VERSION ""

NS_ :

BS_:

BU_: EBCM EON CAM RADAR PCM EPS VSA SCM BDY XXX EPB EO E

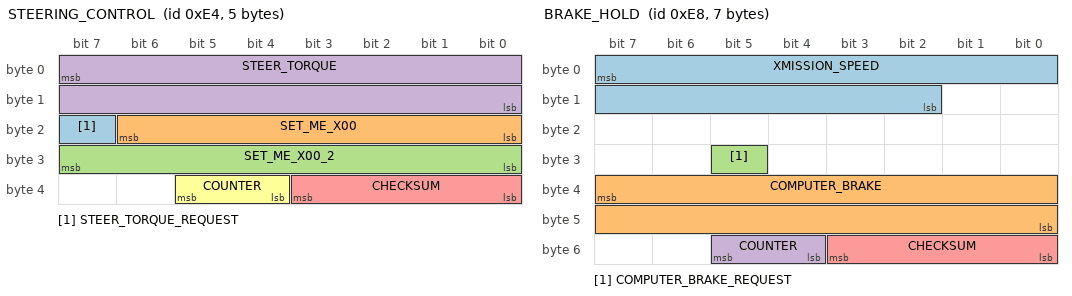
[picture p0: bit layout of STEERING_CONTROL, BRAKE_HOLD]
BO_ 228 STEERING_CONTROL: 5 EON
 SG_ STEER_TORQUE_REQUEST : 23|1@0+ (1,0) [0|1] "" EPS
 SG_ SET_ME_X00 : 22|7@0+ (1,0) [0|127] "" EPS
 SG_ SET_ME_X00_2 : 31|8@0+ (1,0) [0|0] "" EPS
 SG_ STEER_TORQUE : 7|16@0- (1,0) [-4096|4096] "" EPS
 SG_ CHECKSUM : 35|4@0+ (1,0) [0|15] "" EPS
 SG_ COUNTER : 37|2@0+ (1,0) [0|3] "" EPS

BO_ 232 BRAKE_HOLD: 7 XXX
 SG_ XMISSION_SPEED : 7|14@0- (1,0) [1|0] "" XXX
 SG_ COMPUTER_BRAKE : 39|16@0+ (1,0) [0|0] "" XXX
 SG_ COMPUTER_BRAKE_REQUEST : 29|1@0+ (1,0) [0|0] "" XXX
 SG_ COUNTER : 53|2@0+ (1,0) [0|3] "" XXX
 SG_ CHECKSUM : 51|4@0+ (1,0) [0|15] "" XXX

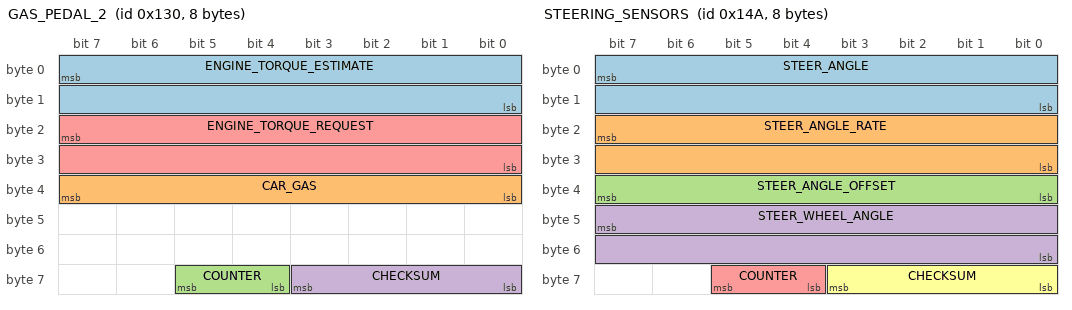
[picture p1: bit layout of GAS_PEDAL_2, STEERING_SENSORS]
BO_ 304 GAS_PEDAL_2: 8 PCM
 SG_ ENGINE_TORQUE_ESTIMATE : 7|16@0- (1,0) [-1000|1000] "Nm" EON
 SG_ CAR_GAS : 39|8@0+ (1,0) [0|255] "" EON
 SG_ COUNTER : 61|2@0+ (1,0) [0|3] "" EON
 SG_ CHECKSUM : 59|4@0+ (1,0) [0|15] "" EON
 SG_ ENGINE_TORQUE_REQUEST : 23|16@0- (0.01,0) [-1000|1000] "Nm" EON

BO_ 330 STEERING_SENSORS: 8 EPS
 SG_ STEER_ANGLE : 7|16@0- (-0.1,0) [-500|500] "deg" EON
 SG_ STEER_ANGLE_RATE : 23|16@0- (-1,0) [-3000|3000] "deg/s" EON
 SG_ STEER_ANGLE_OFFSET : 39|8@0- (-0.1,0) [-128|127] "deg" EON
 SG_ STEER_WHEEL_ANGLE : 47|16@0- (-0.1,0) [-500|500] "deg" EON
 SG_ COUNTER : 61|2@0+ (1,0) [0|3] "" EON
 SG_ CHECKSUM : 59|4@0+ (1,0) [0|15] "" EON

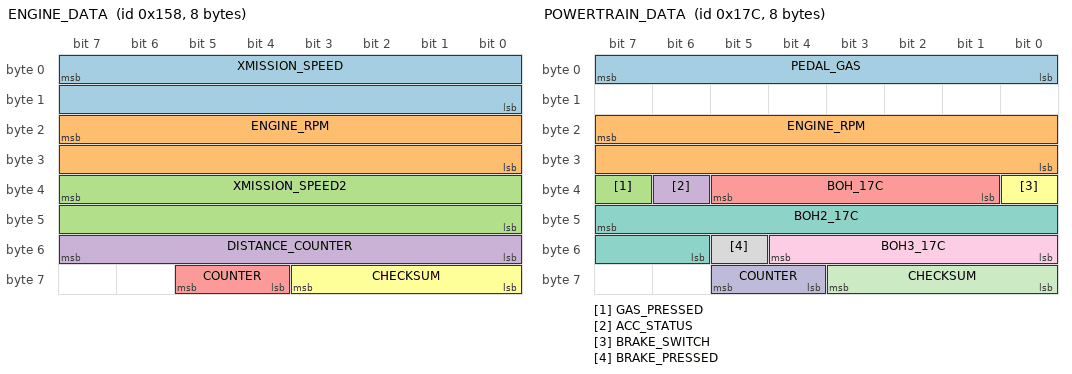
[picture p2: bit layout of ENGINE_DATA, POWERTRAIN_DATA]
BO_ 344 ENGINE_DATA: 8 PCM
 SG_ XMISSION_SPEED : 7|16@0+ (0.002759506,0) [0|70] "m/s" EON
 SG_ ENGINE_RPM : 23|16@0+ (1,0) [0|15000] "rpm" EON
 SG_ XMISSION_SPEED2 : 39|16@0+ (0.002759506,0) [0|70] "m/s" EON
 SG_ DISTANCE_COUNTER : 55|8@0+ (10,0) [0|2550] "Meters" XXX
 SG_ COUNTER : 61|2@0+ (1,0) [0|3] "" EON
 SG_ CHECKSUM : 59|4@0+ (1,0) [0|15] "" EON

BO_ 380 POWERTRAIN_DATA: 8 PCM
 SG_ PEDAL_GAS : 7|8@0+ (1,0) [0|255] "" EON
 SG_ ENGINE_RPM : 23|16@0+ (1,0) [0|15000] "rpm" EON
 SG_ GAS_PRESSED : 39|1@0+ (1,0) [0|1] "" EON
 SG_ ACC_STATUS : 38|1@0+ (1,0) [0|1] "" EON
 SG_ BOH_17C : 37|5@0+ (1,0) [0|1] "" EON
 SG_ BRAKE_SWITCH : 32|1@0+ (1,0) [0|1] "" EON
 SG_ BOH2_17C : 47|10@0+ (1,0) [0|1] "" EON
 SG_ BRAKE_PRESSED : 53|1@0+ (1,0) [0|1] "" EON
 SG_ BOH3_17C : 52|5@0+ (1,0) [0|1] "" EON
 SG_ COUNTER : 61|2@0+ (1,0) [0|3] "" EON
 SG_ CHECKSUM : 59|4@0+ (1,0) [0|15] "" EON

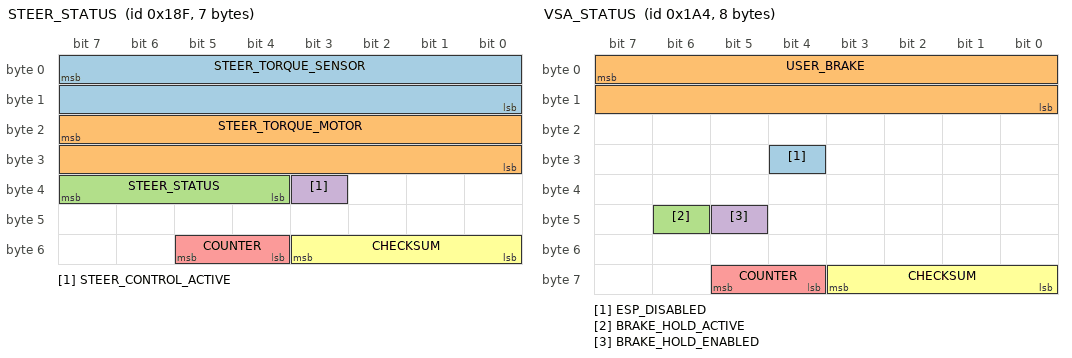
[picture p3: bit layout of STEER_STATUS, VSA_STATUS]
BO_ 399 STEER_STATUS: 7 EPS
 SG_ STEER_TORQUE_SENSOR : 7|16@0- (1,0) [-31000|31000] "tbd" EON
 SG_ STEER_TORQUE_MOTOR : 23|16@0- (1,0) [-31000|31000] "tbd" EON
 SG_ STEER_STATUS : 39|4@0+ (1,0) [0|15] "" EON
 SG_ STEER_CONTROL_ACTIVE : 35|1@0+ (1,0) [0|1] "" EON
 SG_ COUNTER : 53|2@0+ (1,0) [0|3] "" EON
 SG_ CHECKSUM : 51|4@0+ (1,0) [0|15] "" EON

BO_ 420 VSA_STATUS: 8 VSA
 SG_ ESP_DISABLED : 28|1@0+ (1,0) [0|1] "" EON
 SG_ USER_BRAKE : 7|16@0+ (0.015625,-1.609375) [0|1000] "" EON
 SG_ BRAKE_HOLD_ACTIVE : 46|1@0+ (1,0) [0|1] "" EON
 SG_ BRAKE_HOLD_ENABLED : 45|1@0+ (1,0) [0|1] "" EON
 SG_ COUNTER : 61|2@0+ (1,0) [0|3] "" EON
 SG_ CHECKSUM : 59|4@0+ (1,0) [0|15] "" EON

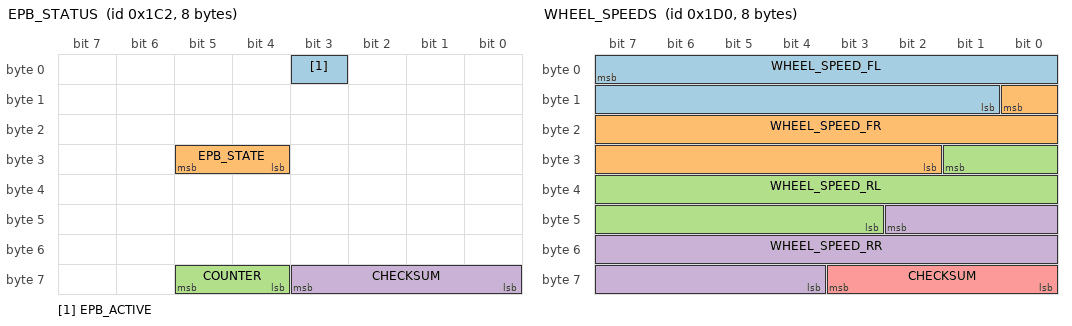
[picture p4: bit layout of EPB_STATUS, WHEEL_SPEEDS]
BO_ 450 EPB_STATUS: 8 EPB
 SG_ EPB_ACTIVE : 3|1@0+ (1,0) [0|1] "" EON
 SG_ EPB_STATE : 29|2@0+ (1,0) [0|3] "" EON
 SG_ COUNTER : 61|2@0+ (1,0) [0|3] "" XXX
 SG_ CHECKSUM : 59|4@0+ (1,0) [0|15] "" XXX

BO_ 464 WHEEL_SPEEDS: 8 VSA
 SG_ WHEEL_SPEED_FL : 7|15@0+ (0.01,0) [0|250] "kph" EON
 SG_ WHEEL_SPEED_FR : 8|15@0+ (0.01,0) [0|250] "kph" EON
 SG_ WHEEL_SPEED_RL : 25|15@0+ (0.01,0) [0|250] "kph" EON
 SG_ WHEEL_SPEED_RR : 42|15@0+ (0.01,0) [0|250] "kph" EON
 SG_ CHECKSUM : 59|4@0+ (1,0) [0|3] "" EON

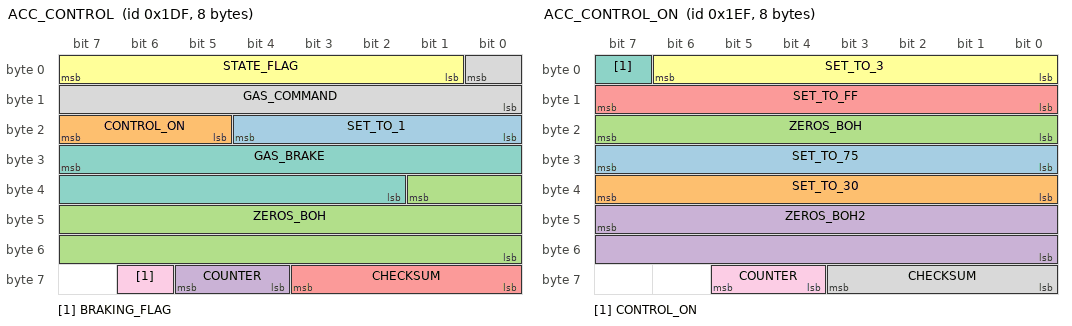
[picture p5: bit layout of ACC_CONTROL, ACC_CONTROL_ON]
BO_ 479 ACC_CONTROL: 8 EON
 SG_ SET_TO_1 : 20|5@0+ (1,0) [0|1] "" PCM
 SG_ CONTROL_ON : 23|3@0+ (1,0) [0|5] "" XXX
 SG_ ZEROS_BOH : 33|18@0+ (1,0) [100|100] "" XXX
 SG_ COUNTER : 61|2@0+ (1,0) [0|3] "" XXX
 SG_ CHECKSUM : 59|4@0+ (1,0) [0|15] "" XXX
 SG_ STATE_FLAG : 7|7@0+ (1,0) [0|69] "" XXX
 SG_ GAS_BRAKE : 31|14@0- (0.001,0) [0|1] "" XXX
 SG_ GAS_COMMAND : 0|9@0+ (0.001,0) [0|1] "" PCM
 SG_ BRAKING_FLAG : 62|1@0+ (1,0) [0|1] "" XXX

BO_ 495 ACC_CONTROL_ON: 8 XXX
 SG_ SET_TO_75 : 31|8@0+ (1,0) [0|255] "" XXX
 SG_ SET_TO_30 : 39|8@0+ (1,0) [0|255] "" XXX
 SG_ ZEROS_BOH : 23|8@0+ (1,0) [0|255] "" XXX
 SG_ ZEROS_BOH2 : 47|16@0+ (1,0) [0|255] "" XXX
 SG_ SET_TO_FF : 15|8@0+ (1,0) [0|255] "" XXX
 SG_ SET_TO_3 : 6|7@0+ (1,0) [0|4095] "" XXX
 SG_ CONTROL_ON : 7|1@0+ (1,0) [0|1] "" XXX
 SG_ CHECKSUM : 59|4@0+ (1,0) [0|15] "" XXX
 SG_ COUNTER : 61|2@0+ (1,0) [0|3] "" XXX

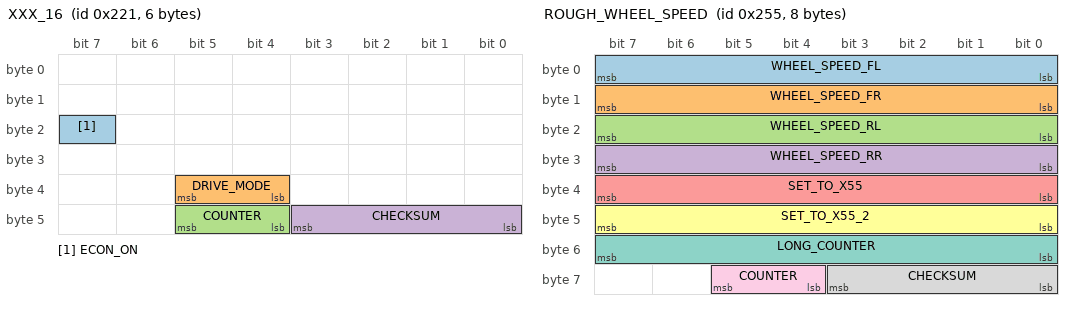
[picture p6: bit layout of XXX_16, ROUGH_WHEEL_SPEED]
BO_ 545 XXX_16: 6 SCM
 SG_ ECON_ON : 23|1@0+ (1,0) [0|1] "" XXX
 SG_ DRIVE_MODE : 37|2@0+ (1,0) [0|3] "" XXX
 SG_ COUNTER : 45|2@0+ (1,0) [0|3] "" BDY
 SG_ CHECKSUM : 43|4@0+ (1,0) [0|15] "" BDY

BO_ 597 ROUGH_WHEEL_SPEED: 8 VSA
 SG_ WHEEL_SPEED_FL : 7|8@0+ (1,0) [0|255] "mph" EON
 SG_ WHEEL_SPEED_FR : 15|8@0+ (1,0) [0|255] "mph" EON
 SG_ WHEEL_SPEED_RL : 23|8@0+ (1,0) [0|255] "mph" EON
 SG_ WHEEL_SPEED_RR : 31|8@0+ (1,0) [0|255] "mph" EON
 SG_ SET_TO_X55 : 39|8@0+ (1,0) [0|255] "" XXX
 SG_ SET_TO_X55_2 : 47|8@0+ (1,0) [0|255] "" EON
 SG_ LONG_COUNTER : 55|8@0+ (1,0) [0|255] "" XXX
 SG_ CHECKSUM : 59|4@0+ (1,0) [0|15] "" XXX
 SG_ COUNTER : 61|2@0+ (1,0) [0|3] "" XXX

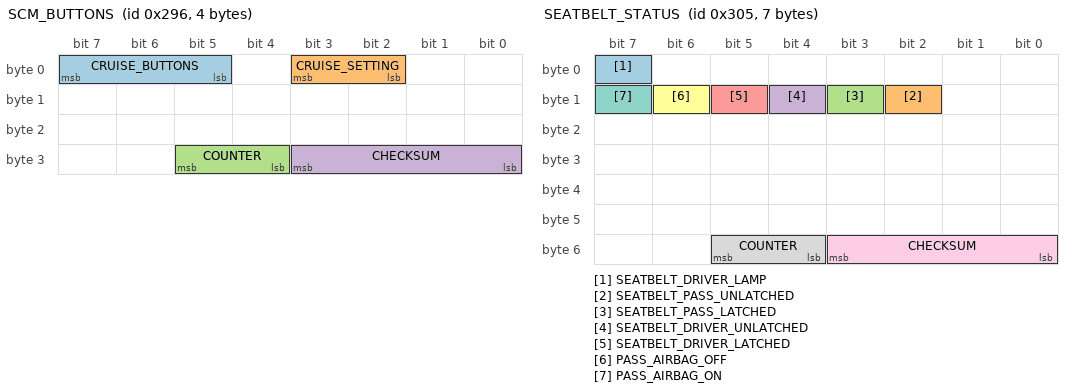
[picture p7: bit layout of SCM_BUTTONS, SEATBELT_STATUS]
BO_ 662 SCM_BUTTONS: 4 SCM
 SG_ CRUISE_BUTTONS : 7|3@0+ (1,0) [0|7] "" EON
 SG_ CRUISE_SETTING : 3|2@0+ (1,0) [0|3] "" EON
 SG_ COUNTER : 29|2@0+ (1,0) [0|3] "" EON
 SG_ CHECKSUM : 27|4@0+ (1,0) [0|15] "" EON

BO_ 773 SEATBELT_STATUS: 7 BDY
 SG_ SEATBELT_DRIVER_LAMP : 7|1@0+ (1,0) [0|1] "" EON
 SG_ SEATBELT_PASS_UNLATCHED : 10|1@0+ (1,0) [0|1] "" EON
 SG_ SEATBELT_PASS_LATCHED : 11|1@0+ (1,0) [0|1] "" EON
 SG_ SEATBELT_DRIVER_UNLATCHED : 12|1@0+ (1,0) [0|1] "" EON
 SG_ SEATBELT_DRIVER_LATCHED : 13|1@0+ (1,0) [0|1] "" EON
 SG_ PASS_AIRBAG_OFF : 14|1@0+ (1,0) [0|1] "" EON
 SG_ PASS_AIRBAG_ON : 15|1@0+ (1,0) [0|1] "" EON
 SG_ COUNTER : 53|2@0+ (1,0) [0|3] "" EON
 SG_ CHECKSUM : 51|4@0+ (1,0) [0|3] "" EON

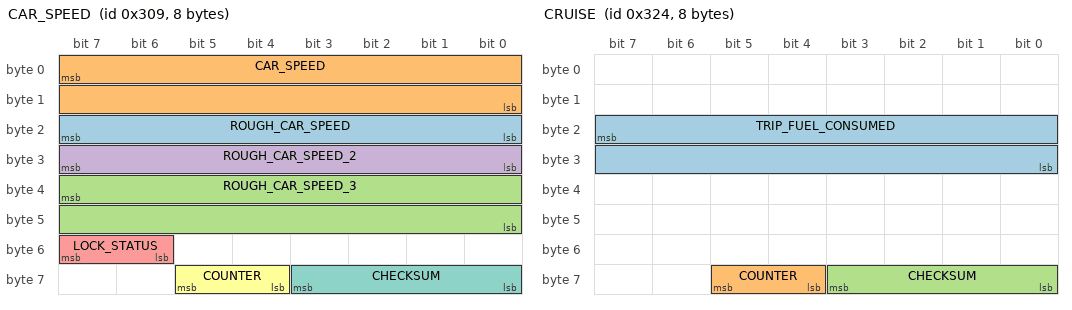
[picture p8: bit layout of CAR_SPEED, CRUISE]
BO_ 777 CAR_SPEED: 8 PCM
 SG_ ROUGH_CAR_SPEED : 23|8@0+ (1,0) [0|255] "" XXX
 SG_ CAR_SPEED : 7|16@0+ (1,0) [0|65535] "" XXX
 SG_ ROUGH_CAR_SPEED_3 : 39|16@0+ (1,0) [0|65535] "" XXX
 SG_ ROUGH_CAR_SPEED_2 : 31|8@0+ (1,0) [0|255] "" XXX
 SG_ LOCK_STATUS : 55|2@0+ (1,0) [0|255] "" XXX
 SG_ COUNTER : 61|2@0+ (1,0) [0|3] "" XXX
 SG_ CHECKSUM : 59|4@0+ (1,0) [0|15] "" XXX

BO_ 780 ACC_HUD: 8 ADAS
 SG_ CRUISE_SPEED : 31|8@0+ (1,0) [0|255] "" BDY
 SG_ DTC_MODE : 39|1@0+ (1,0) [0|1] "" BDY
 SG_ BOH : 38|1@0+ (1,0) [0|1] "" BDY
 SG_ FCM_PROBLEM : 34|1@0+ (1,0) [0|1] "" BDY
 SG_ RADAR_OBSTRUCTED : 33|1@0+ (1,0) [0|1] "" BDY
 SG_ ENABLE_MINI_CAR : 32|1@0+ (1,0) [0|1] "" BDY
 SG_ BOH_3 : 43|1@0+ (1,0) [0|3] "" BDY
 SG_ BOH_4 : 42|1@0+ (1,0) [0|3] "" BDY
 SG_ BOH_5 : 41|1@0+ (1,0) [0|3] "" BDY
 SG_ CRUISE_CONTROL_LABEL : 40|1@0+ (1,0) [0|3] "" BDY
 SG_ ZEROS_BOH : 7|24@0+ (0.002759506,0) [0|100] "m/s" BDY
 SG_ FCM_OFF : 35|1@0+ (1,0) [0|1] "" BDY
 SG_ SET_TO_1 : 36|1@0+ (1,0) [0|1] "" XXX
 SG_ HUD_DISTANCE : 47|2@0+ (1,0) [0|3] "" BDY
 SG_ HUD_LEAD : 45|2@0+ (1,0) [0|3] "" BDY
 SG_ ACC_PROBLEM : 37|1@0+ (1,0) [0|1] "" BDY
 SG_ ACC_ON : 52|1@0+ (1,0) [0|1] "" XXX
 SG_ BOH_6 : 51|4@0+ (1,0) [0|15] "" XXX
 SG_ SET_TO_X3 : 55|2@0+ (1,0) [0|3] "" XXX
 SG_ COUNTER : 61|2@0+ (1,0) [0|3] "" XXX
 SG_ CHECKSUM : 59|4@0+ (1,0) [0|15] "" XXX

BO_ 804 CRUISE: 8 PCM
 SG_ TRIP_FUEL_CONSUMED : 23|16@0+ (1,0) [0|255] "" EON
 SG_ COUNTER : 61|2@0+ (1,0) [0|3] "" EON
 SG_ CHECKSUM : 59|4@0+ (1,0) [0|15] "" EON

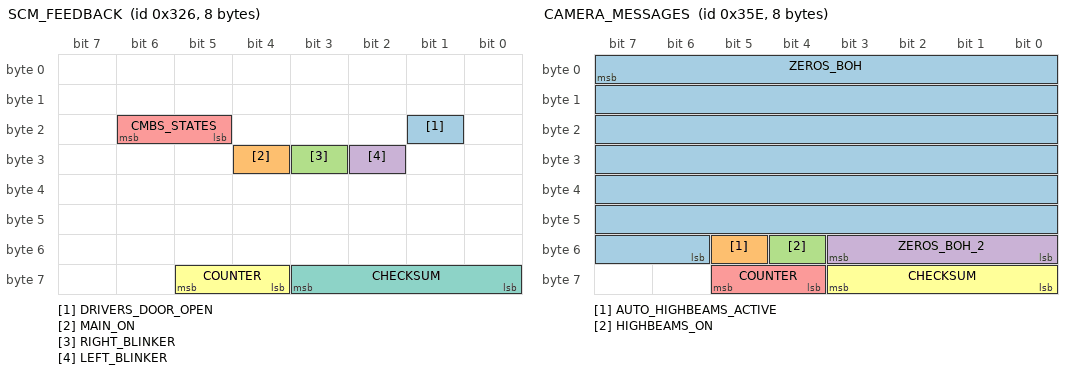
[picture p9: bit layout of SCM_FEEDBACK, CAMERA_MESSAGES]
BO_ 806 SCM_FEEDBACK: 8 SCM
 SG_ DRIVERS_DOOR_OPEN : 17|1@0+ (1,0) [0|1] "" XXX
 SG_ MAIN_ON : 28|1@0+ (1,0) [0|1] "" EON
 SG_ RIGHT_BLINKER : 27|1@0+ (1,0) [0|1] "" EON
 SG_ LEFT_BLINKER : 26|1@0+ (1,0) [0|1] "" EON
 SG_ CMBS_STATES : 22|2@0+ (1,0) [0|3] "" EON
 SG_ COUNTER : 61|2@0+ (1,0) [0|3] "" XXX
 SG_ CHECKSUM : 59|4@0+ (1,0) [0|15] "" XXX

BO_ 829 LKAS_HUD: 5 ADAS
 SG_ CAM_TEMP_HIGH : 7|1@0+ (1,0) [0|255] "" BDY
 SG_ SET_ME_X41 : 6|7@0+ (1,0) [0|127] "" BDY
 SG_ BOH : 23|2@0+ (1,0) [0|4] "" BDY
 SG_ DASHED_LANES : 14|1@0+ (1,0) [0|1] "" BDY
 SG_ DTC : 13|1@0+ (1,0) [0|1] "" BDY
 SG_ LKAS_PROBLEM : 12|1@0+ (1,0) [0|1] "" BDY
 SG_ LKAS_OFF : 11|1@0+ (1,0) [0|1] "" BDY
 SG_ SOLID_LANES : 10|1@0+ (1,0) [0|1] "" BDY
 SG_ LDW_RIGHT : 9|1@0+ (1,0) [0|1] "" BDY
 SG_ STEERING_REQUIRED : 8|1@0+ (1,0) [0|1] "" BDY
 SG_ LDW_PROBLEM : 21|1@0+ (1,0) [0|1] "" BDY
 SG_ BEEP : 17|2@0+ (1,0) [0|1] "" BDY
 SG_ LDW_ON : 28|1@0+ (1,0) [0|1] "" BDY
 SG_ LDW_OFF : 27|1@0+ (1,0) [0|1] "" BDY
 SG_ CLEAN_WINDSHIELD : 26|1@0+ (1,0) [0|1] "" BDY
 SG_ SET_ME_X48 : 31|8@0+ (1,0) [0|255] "" BDY
 SG_ COUNTER : 37|2@0+ (1,0) [0|3] "" BDY
 SG_ CHECKSUM : 35|4@0+ (1,0) [0|15] "" BDY

BO_ 862 CAMERA_MESSAGES: 8 CAM
 SG_ ZEROS_BOH : 7|50@0+ (1,0) [0|127] "" BDY
 SG_ AUTO_HIGHBEAMS_ACTIVE : 53|1@0+ (1,0) [0|1] "" XXX
 SG_ HIGHBEAMS_ON : 52|1@0+ (1,0) [0|1] "" XXX
 SG_ ZEROS_BOH_2 : 51|4@0+ (1,0) [0|15] "" XXX
 SG_ COUNTER : 61|2@0+ (1,0) [0|3] "" XXX
 SG_ CHECKSUM : 59|4@0+ (1,0) [0|15] "" XXX

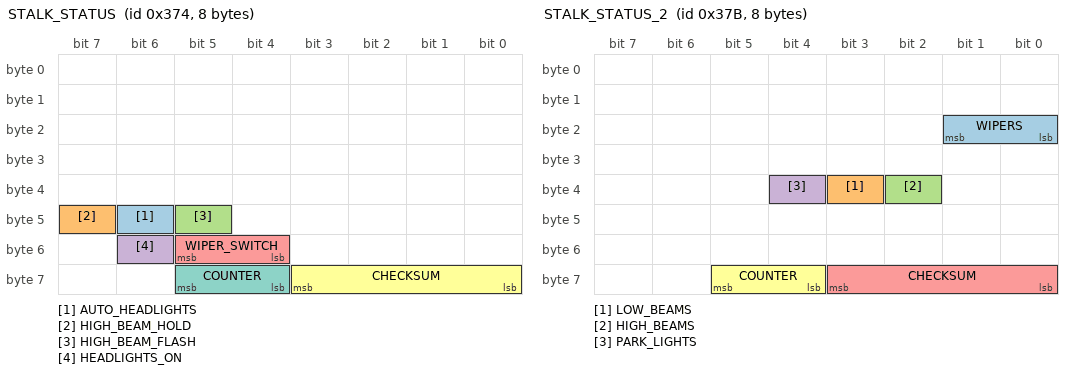
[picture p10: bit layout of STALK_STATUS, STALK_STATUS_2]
BO_ 884 STALK_STATUS: 8 XXX
 SG_ AUTO_HEADLIGHTS : 46|1@0+ (1,0) [0|1] "" EON
 SG_ HIGH_BEAM_HOLD : 47|1@0+ (1,0) [0|1] "" EON
 SG_ HIGH_BEAM_FLASH : 45|1@0+ (1,0) [0|1] "" EON
 SG_ HEADLIGHTS_ON : 54|1@0+ (1,0) [0|1] "" EON
 SG_ WIPER_SWITCH : 53|2@0+ (1,0) [0|3] "" XXX
 SG_ CHECKSUM : 59|4@0+ (1,0) [0|3] "" EON
 SG_ COUNTER : 61|2@0+ (1,0) [0|3] "" EON

BO_ 891 STALK_STATUS_2: 8 XXX
 SG_ WIPERS : 17|2@0+ (1,0) [0|3] "" EON
 SG_ LOW_BEAMS : 35|1@0+ (1,0) [0|1] "" XXX
 SG_ HIGH_BEAMS : 34|1@0+ (1,0) [0|1] "" XXX
 SG_ PARK_LIGHTS : 36|1@0+ (1,0) [0|1] "" XXX
 SG_ CHECKSUM : 59|4@0+ (1,0) [0|3] "" EON
 SG_ COUNTER : 61|2@0+ (1,0) [0|3] "" EON

BO_ 401 GEARBOX: 8 PCM

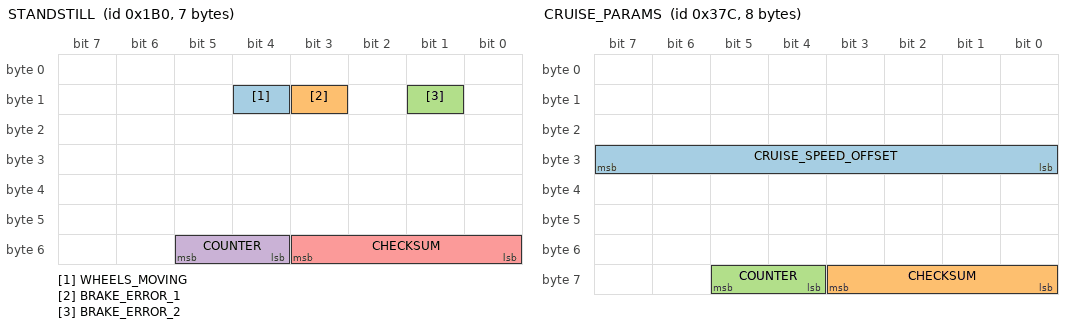
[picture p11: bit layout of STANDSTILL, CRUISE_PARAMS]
BO_ 432 STANDSTILL: 7 VSA
 SG_ WHEELS_MOVING : 12|1@0+ (1,0) [0|1] "" EON
 SG_ BRAKE_ERROR_1 : 11|1@0+ (1,0) [0|1] "" EON
 SG_ BRAKE_ERROR_2 : 9|1@0+ (1,0) [0|1] "" EON
 SG_ COUNTER : 53|2@0+ (1,0) [0|3] "" EON
 SG_ CHECKSUM : 51|4@0+ (1,0) [0|15] "" EON

BO_ 892 CRUISE_PARAMS: 8 PCM
 SG_ CRUISE_SPEED_OFFSET : 31|8@0- (0.1,0) [-128|127] "kph" EON
 SG_ CHECKSUM : 59|4@0+ (1,0) [0|3] "" EON
 SG_ COUNTER : 61|2@0+ (1,0) [0|15] "" EON

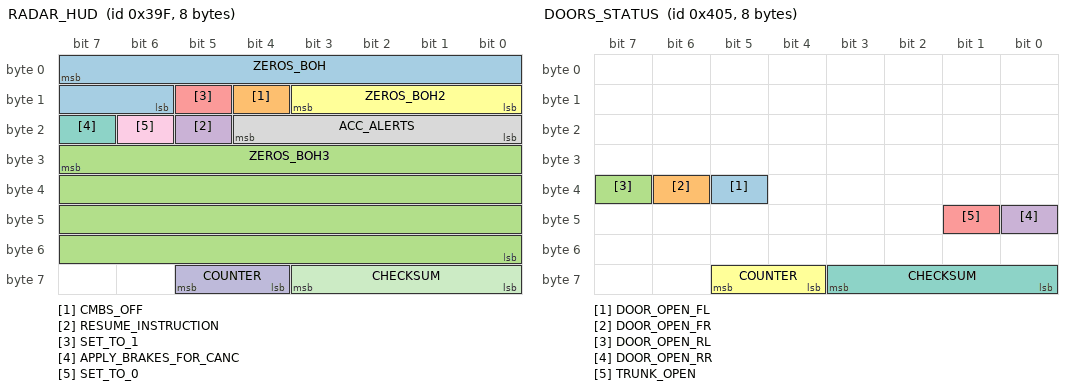
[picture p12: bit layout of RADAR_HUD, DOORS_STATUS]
BO_ 927 RADAR_HUD: 8 RADAR
 SG_ ZEROS_BOH : 7|10@0+ (1,0) [0|127] "" BDY
 SG_ CMBS_OFF : 12|1@0+ (1,0) [0|1] "" BDY
 SG_ ZEROS_BOH3 : 31|32@0+ (1,0) [0|4294967295] "" XXX
 SG_ RESUME_INSTRUCTION : 21|1@0+ (1,0) [0|1] "" XXX
 SG_ SET_TO_1 : 13|1@0+ (1,0) [0|1] "" BDY
 SG_ ZEROS_BOH2 : 11|4@0+ (1,0) [0|1] "" XXX
 SG_ APPLY_BRAKES_FOR_CANC : 23|1@0+ (1,0) [0|1] "" XXX
 SG_ ACC_ALERTS : 20|5@0+ (1,0) [0|1] "" BDY
 SG_ SET_TO_0 : 22|1@0+ (1,0) [0|1] "" XXX
 SG_ COUNTER : 61|2@0+ (1,0) [0|3] "" XXX
 SG_ CHECKSUM : 59|4@0+ (1,0) [0|15] "" XXX

BO_ 1029 DOORS_STATUS: 8 BDY
 SG_ DOOR_OPEN_FL : 37|1@0+ (1,0) [0|1] "" EON
 SG_ DOOR_OPEN_FR : 38|1@0+ (1,0) [0|1] "" EON
 SG_ DOOR_OPEN_RL : 39|1@0+ (1,0) [0|1] "" EON
 SG_ DOOR_OPEN_RR : 40|1@0+ (1,0) [0|1] "" EON
 SG_ TRUNK_OPEN : 41|1@0+ (1,0) [0|1] "" EON
 SG_ COUNTER : 61|2@0+ (1,0) [0|3] "" EON
 SG_ CHECKSUM : 59|4@0+ (1,0) [0|15] "" EON

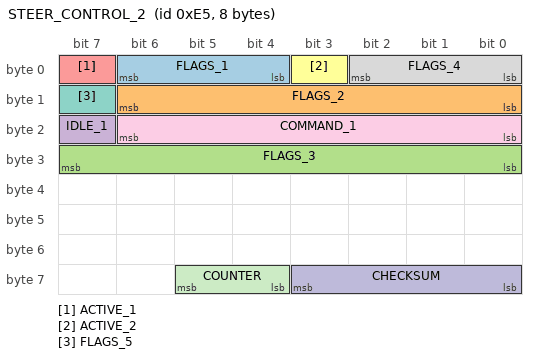
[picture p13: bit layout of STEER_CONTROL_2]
BO_ 229 STEER_CONTROL_2: 8 XXX
 SG_ FLAGS_1 : 4|3@1+ (1,0) [0|255] "" XXX
 SG_ FLAGS_2 : 8|7@1+ (1,0) [0|255] "" XXX
 SG_ FLAGS_3 : 24|8@1+ (1,0) [0|255] "" XXX
 SG_ IDLE_1 : 23|1@0+ (1,0) [0|1] "" XXX
 SG_ ACTIVE_1 : 7|1@0+ (1,0) [0|1] "" XXX
 SG_ ACTIVE_2 : 3|1@0+ (1,0) [0|1] "" XXX
 SG_ FLAGS_5 : 15|1@0+ (1,0) [0|1] "" XXX
 SG_ FLAGS_4 : 0|3@1+ (1,0) [0|15] "" XXX
 SG_ COMMAND_1 : 16|7@1- (1,0) [-127|127] "" XXX
 SG_ CHECKSUM : 59|4@0+ (1,0) [0|15] "" XXX
 SG_ COUNTER : 61|2@0+ (1,0) [0|3] "" XXX

VAL_ 662 CRUISE_BUTTONS 7 "tbd" 6 "tbd" 5 "tbd" 4 "accel_res" 3 "decel_set" 2 "cancel" 1 "main" 0 "none" ;
VAL_ 662 CRUISE_SETTING 3 "distance_adj" 2 "tbd" 1 "lkas_button" 0 "none" ;
VAL_ 829 BEEP 3 "single_beep" 2 "triple_beep" 1 "repeated_beep" 0 "no_beep" ;
VAL_ 891 WIPERS 4 "High" 2 "Low" 0 "Off" ;
CM_ "AUTOGENERATED FILE, DO NOT EDIT"
CM_ "Imported file _bosch_2018.dbc s";
CM_ "Imported file _bosch_2018.dbc st
CM_ "Imported file _bosch_2018.dbc st";
CM_ "Imported file _bosch_2018.dbc sta
CM_ "Imported file _bosch_2018.dbc st";
CM_ "Imported file _bosch_2018.dbc sta
CM_ "Imported file _bosch_2018.dbc sta";
CM_ "Imported file _bosch_2018.dbc star
CM_ "Imported file _bosch_2018.dbc st";
CM_ "Imported file _bosch_2018.dbc sta
CM_ "Imported file _bosch_2018.dbc sta";
CM_ "Imported file _bosch_2018.dbc star
CM_ "Imported file _bosch_2018.dbc sta";
CM_ "Imported file _bosch_2018.dbc star
CM_ "Imported file _bosch_2018.dbc star";
CM_ "Imported file _bosch_2018.dbc start
CM_ "Imported file _bosch_2018.dbc st";
CM_ "Imported file _bosch_2018.dbc sta
CM_ "Imported file _bosch_2018.dbc sta";
CM_ "Imported file _bosch_2018.dbc star
CM_ "Imported file _bosch_2018.dbc sta";
CM_ "Imported file _bosch_2018.dbc star
CM_ "Imported file _bosch_2018.dbc star";
CM_ "Imported file _bosch_2018.dbc start
CM_ "Imported file _bosch_2018.dbc sta";
CM_ "Imported file _bosch_2018.dbc star
CM_ "Imported file _bosch_2018.dbc star";
CM_ "Imported file _bosch_2018.dbc start
CM_ "Imported file _bosch_2018.dbc star";
CM_ "Imported file _bosch_2018.dbc start
CM_ "Imported file _bosch_2018.dbc start";
CM_ "Imported file _bosch_2018.dbc starts
CM_ "Imported file _bosch_2018.dbc s";
CM_ "Imported file _bosch_2018.dbc st
CM_ "Imported file _bosch_2018.dbc st";
CM_ "Imported file _bosch_2018.dbc sta
CM_ "Imported file _bosch_2018.dbc st";
CM_ "Imported file _bosch_2018.dbc sta
CM_ "Imported file _bosch_2018.dbc sta";
CM_ "Imported file _bosch_2018.dbc star
CM_ "Imported file _bosch_2018.dbc st";
CM_ "Imported file _bosch_2018.dbc sta
CM_ "Imported file _bosch_2018.dbc sta";
CM_ "Imported file _bosch_2018.dbc star
CM_ "Imported file _bosch_2018.dbc sta";
CM_ "Imported file _bosch_2018.dbc star
CM_ "Imported file _bosch_2018.dbc star";
CM_ "Imported file _bosch_2018.dbc start
CM_ "Imported file _bosch_2018.dbc st";
CM_ "Imported file _bosch_2018.dbc sta
CM_ "Imported file _bosch_2018.dbc sta";
CM_ "Imported file _bosch_2018.dbc star
CM_ "Imported file _bosch_2018.dbc sta";
CM_ "Imported file _bosch_2018.dbc star
CM_ "Imported file _bosch_2018.dbc star";
CM_ "Imported file _bosch_2018.dbc start
CM_ "Imported file _bosch_2018.dbc sta";
CM_ "Imported file _bosch_2018.dbc star
CM_ "Imported file _bosch_2018.dbc star";
CM_ "Imported file _bosch_2018.dbc start
CM_ "Imported file _bosch_2018.dbc star";
CM_ "Imported file _bosch_2018.dbc start
CM_ "Imported file _bosch_2018.dbc start";
CM_ "Imported file _bosch_2018.dbc starts
CM_ "Imported file _bosch_2018.dbc st";
CM_ "Imported file _bosch_2018.dbc sta
CM_ "Imported file _bosch_2018.dbc sta";
CM_ "Imported file _bosch_2018.dbc star
CM_ "Imported file _bosch_2018.dbc sta";
CM_ "Imported file _bosch_2018.dbc star
CM_ "Imported file _bosch_2018.dbc star";
CM_ "Imported file _bosch_2018.dbc start
CM_ "Imported file _bosch_2018.dbc sta";
CM_ "Imported file _bosch_2018.dbc star
CM_ "Imported file _bosch_2018.dbc star";
CM_ "Imported file _bosch_2018.dbc start
CM_ "Imported file _bosch_2018.dbc star";
CM_ "Imported file _bosch_2018.dbc start
CM_ "Imported file _bosch_2018.dbc start";
CM_ "Imported file _bosch_2018.dbc starts
CM_ "Imported file _bosch_2018.dbc st";
CM_ "Imported file _bosch_2018.dbc sta
CM_ "Imported file _bosch_2018.dbc sta";
CM_ "Imported file _bosch_2018.dbc star
CM_ "Imported file _bosch_2018.dbc sta";
CM_ "Imported file _bosch_2018.dbc star
CM_ "Imported file _bosch_2018.dbc star";
CM_ "Imported file _bosch_2018.dbc start
CM_ "Imported file _bosch_2018.dbc sta";
CM_ "Imported file _bosch_2018.dbc star
CM_ "Imported file _bosch_2018.dbc star";
CM_ "Imported file _bosch_2018.dbc start
CM_ "Imported file _bosch_2018.dbc star";
CM_ "Imported file _bosch_2018.dbc start
CM_ "Imported file _bosch_2018.dbc start";
CM_ "Imported file _bosch_2018.dbc starts
CM_ "Imported file _bosch_2018.dbc sta";
CM_ "Imported file _bosch_2018.dbc star
CM_ "Imported file _bosch_2018.dbc star";
CM_ "Imported file _bosch_2018.dbc start
CM_ "Imported file _bosch_2018.dbc star";
CM_ "Imported file _bosch_2018.dbc start
CM_ "Imported file _bosch_2018.dbc start";
CM_ "Imported file _bosch_2018.dbc starts
CM_ "Imported file _bosch_2018.dbc sta";
CM_ "Imported file _bosch_2018.dbc star
CM_ "Imported file _bosch_2018.dbc star";
CM_ "Imported file _bosch_2018.dbc start
CM_ "Imported file _bosch_2018.dbc star";
CM_ "Imported file _bosch_2018.dbc start
CM_ "Imported file _bosch_2018.dbc start";
CM_ "Imported file _bosch_2018.dbc starts
CM_ "Imported file _bosch_2018.dbc star";
CM_ "Imported file _bosch_2018.dbc start
CM_ "Imported file _bosch_2018.dbc start";
CM_ "Imported file _bosch_2018.dbc starts
CM_ "Imported file _bosch_2018.dbc star";
CM_ "Imported file _bosch_2018.dbc start
CM_ "Imported file _bosch_2018.dbc start";
CM_ "Imported file _bosch_2018.dbc starts
CM_ "Imported file _bosch_2018.dbc start";
CM_ "Imported file _bosch_2018.dbc starts
CM_ "Imported file _bosch_2018.dbc start";
CM_ "Imported file _bosch_2018.dbc starts
CM_ "Imported file _bosch_2018.dbc starts";
CM_ "Imported file _bosch_2018.dbc starts 
CM_ "Imported file _bosch_2018.dbc starts ";
CM_ "Imported file _bosch_2018.dbc starts h
CM_ "Imported file _bosch_2018.dbc st";
CM_ "Imported file _bosch_2018.dbc sta
CM_ "Imported file _bosch_2018.dbc sta";
CM_ "Imported file _bosch_2018.dbc star
CM_ "Imported file _bosch_2018.dbc sta";
CM_ "Imported file _bosch_2018.dbc star
CM_ "Imported file _bosch_2018.dbc star";
CM_ "Imported file _bosch_2018.dbc start
CM_ "Imported file _bosch_2018.dbc sta";
CM_ "Imported file _bosch_2018.dbc star
CM_ "Imported file _bosch_2018.dbc star";
CM_ "Imported file _bosch_2018.dbc start
CM_ "Imported file _bosch_2018.dbc star";
CM_ "Imported file _bosch_2018.dbc start
CM_ "Imported file _bosch_2018.dbc start";
CM_ "Imported file _bosch_2018.dbc starts
CM_ "Imported file _bosch_2018.dbc st";
CM_ "Imported file _bosch_2018.dbc sta
CM_ "Imported file _bosch_2018.dbc sta";
CM_ "Imported file _bosch_2018.dbc star
CM_ "Imported file _bosch_2018.dbc sta";
CM_ "Imported file _bosch_2018.dbc star
CM_ "Imported file _bosch_2018.dbc star";
CM_ "Imported file _bosch_2018.dbc start
CM_ "Imported file _bosch_2018.dbc sta";
CM_ "Imported file _bosch_2018.dbc star
CM_ "Imported file _bosch_2018.dbc star";
CM_ "Imported file _bosch_2018.dbc start
CM_ "Imported file _bosch_2018.dbc star";
CM_ "Imported file _bosch_2018.dbc start
CM_ "Imported file _bosch_2018.dbc start";
CM_ "Imported file _bosch_2018.dbc starts
CM_ "Imported file _bosch_2018.dbc sta";
CM_ "Imported file _bosch_2018.dbc star
CM_ "Imported file _bosch_2018.dbc star";
CM_ "Imported file _bosch_2018.dbc start
CM_ "Imported file _bosch_2018.dbc star";
CM_ "Imported file _bosch_2018.dbc start
CM_ "Imported file _bosch_2018.dbc start";
CM_ "Imported file _bosch_2018.dbc starts
CM_ "Imported file _bosch_2018.dbc sta";
CM_ "Imported file _bosch_2018.dbc star
CM_ "Imported file _bosch_2018.dbc star";
CM_ "Imported file _bosch_2018.dbc start
CM_ "Imported file _bosch_2018.dbc star";
CM_ "Imported file _bosch_2018.dbc start
CM_ "Imported file _bosch_2018.dbc start";
CM_ "Imported file _bosch_2018.dbc starts
CM_ "Imported file _bosch_2018.dbc star";
CM_ "Imported file _bosch_2018.dbc start
CM_ "Imported file _bosch_2018.dbc start";
CM_ "Imported file _bosch_2018.dbc starts
CM_ "Imported file _bosch_2018.dbc star";
CM_ "Imported file _bosch_2018.dbc start
CM_ "Imported file _bosch_2018.dbc start";
CM_ "Imported file _bosch_2018.dbc starts
CM_ "Imported file _bosch_2018.dbc start";
CM_ "Imported file _bosch_2018.dbc starts
CM_ "Imported file _bosch_2018.dbc start";
CM_ "Imported file _bosch_2018.dbc starts
CM_ "Imported file _bosch_2018.dbc starts";
CM_ "Imported file _bosch_2018.dbc starts 
CM_ "Imported file _bosch_2018.dbc starts ";
CM_ "Imported file _bosch_2018.dbc starts h
CM_ "Imported file _bosch_2018.dbc sta";
CM_ "Imported file _bosch_2018.dbc star
CM_ "Imported file _bosch_2018.dbc star";
CM_ "Imported file _bosch_2018.dbc start
CM_ "Imported file _bosch_2018.dbc star";
CM_ "Imported file _bosch_2018.dbc start
CM_ "Imported file _bosch_2018.dbc start";
CM_ "Imported file _bosch_2018.dbc starts
CM_ "Imported file _bosch_2018.dbc sta";
CM_ "Imported file _bosch_2018.dbc star
CM_ "Imported file _bosch_2018.dbc star";
CM_ "Imported file _bosch_2018.dbc start
CM_ "Imported file _bosch_2018.dbc star";
CM_ "Imported file _bosch_2018.dbc start
CM_ "Imported file _bosch_2018.dbc start";
CM_ "Imported file _bosch_2018.dbc starts
CM_ "Imported file _bosch_2018.dbc star";
CM_ "Imported file _bosch_2018.dbc start
CM_ "Imported file _bosch_2018.dbc start";
CM_ "Imported file _bosch_2018.dbc starts
CM_ "Imported file _bosch_2018.dbc star";
CM_ "Imported file _bosch_2018.dbc start
CM_ "Imported file _bosch_2018.dbc start";
CM_ "Imported file _bosch_2018.dbc starts
CM_ "Imported file _bosch_2018.dbc start";
CM_ "Imported file _bosch_2018.dbc starts
CM_ "Imported file _bosch_2018.dbc start";
CM_ "Imported file _bosch_2018.dbc starts
CM_ "Imported file _bosch_2018.dbc starts";
CM_ "Imported file _bosch_2018.dbc starts 
CM_ "Imported file _bosch_2018.dbc starts ";
CM_ "Imported file _bosch_2018.dbc starts h
CM_ "Imported file _bosch_2018.dbc star";
CM_ "Imported file _bosch_2018.dbc start
CM_ "Imported file _bosch_2018.dbc start";
CM_ "Imported file _bosch_2018.dbc starts
CM_ "Imported file _bosch_2018.dbc star";
CM_ "Imported file _bosch_2018.dbc start
CM_ "Imported file _bosch_2018.dbc start";
CM_ "Imported file _bosch_2018.dbc starts
CM_ "Imported file _bosch_2018.dbc start";
CM_ "Imported file _bosch_2018.dbc starts
CM_ "Imported file _bosch_2018.dbc start";
CM_ "Imported file _bosch_2018.dbc starts
CM_ "Imported file _bosch_2018.dbc starts";
CM_ "Imported file _bosch_2018.dbc starts 
CM_ "Imported file _bosch_2018.dbc starts ";
CM_ "Imported file _bosch_2018.dbc starts h
CM_ "Imported file _bosch_2018.dbc start";
CM_ "Imported file _bosch_2018.dbc starts
CM_ "Imported file _bosch_2018.dbc start";
CM_ "Imported file _bosch_2018.dbc starts
CM_ "Imported file _bosch_2018.dbc starts";
CM_ "Imported file _bosch_2018.dbc starts 
CM_ "Imported file _bosch_2018.dbc starts ";
CM_ "Imported file _bosch_2018.dbc starts h
CM_ "Imported file _bosch_2018.dbc starts";
CM_ "Imported file _bosch_2018.dbc starts 
CM_ "Imported file _bosch_2018.dbc starts ";
CM_ "Imported file _bosch_2018.dbc starts h
CM_ "Imported file _bosch_2018.dbc starts ";
CM_ "Imported file _bosch_2018.dbc starts h
CM_ "Imported file _bosch_2018.dbc starts h";
CM_ "Imported file _bosch_2018.dbc starts he
CM_ "Imported file _bosch_2018.dbc st";
CM_ "Imported file _bosch_2018.dbc sta
CM_ "Imported file _bosch_2018.dbc sta";
CM_ "Imported file _bosch_2018.dbc star
CM_ "Imported file _bosch_2018.dbc sta";
CM_ "Imported file _bosch_2018.dbc star
CM_ "Imported file _bosch_2018.dbc star";
CM_ "Imported file _bosch_2018.dbc start
CM_ "Imported file _bosch_2018.dbc sta";
CM_ "Imported file _bosch_2018.dbc star
CM_ "Imported file _bosch_2018.dbc star";
CM_ "Imported file _bosch_2018.dbc start
CM_ "Imported file _bosch_2018.dbc star";
CM_ "Imported file _bosch_2018.dbc start
CM_ "Imported file _bosch_2018.dbc start";
CM_ "Imported file _bosch_2018.dbc starts
CM_ "Imported file _bosch_2018.dbc st";
CM_ "Imported file _bosch_2018.dbc sta
CM_ "Imported file _bosch_2018.dbc sta";
CM_ "Imported file _bosch_2018.dbc star
CM_ "Imported file _bosch_2018.dbc sta";
CM_ "Imported file _bosch_2018.dbc star
CM_ "Imported file _bosch_2018.dbc star";
CM_ "Imported file _bosch_2018.dbc start
CM_ "Imported file _bosch_2018.dbc sta";
CM_ "Imported file _bosch_2018.dbc star
CM_ "Imported file _bosch_2018.dbc star";
CM_ "Imported file _bosch_2018.dbc start
CM_ "Imported file _bosch_2018.dbc star";
CM_ "Imported file _bosch_2018.dbc start
CM_ "Imported file _bosch_2018.dbc start";
CM_ "Imported file _bosch_2018.dbc starts
CM_ "Imported file _bosch_2018.dbc sta";
CM_ "Imported file _bosch_2018.dbc star
CM_ "Imported file _bosch_2018.dbc star";
CM_ "Imported file _bosch_2018.dbc start
CM_ "Imported file _bosch_2018.dbc star";
CM_ "Imported file _bosch_2018.dbc start
CM_ "Imported file _bosch_2018.dbc start";
CM_ "Imported file _bosch_2018.dbc starts
CM_ "Imported file _bosch_2018.dbc sta";
CM_ "Imported file _bosch_2018.dbc star
CM_ "Imported file _bosch_2018.dbc star";
CM_ "Imported file _bosch_2018.dbc start
CM_ "Imported file _bosch_2018.dbc star";
CM_ "Imported file _bosch_2018.dbc start
CM_ "Imported file _bosch_2018.dbc start";
CM_ "Imported file _bosch_2018.dbc starts
CM_ "Imported file _bosch_2018.dbc star";
CM_ "Imported file _bosch_2018.dbc start
CM_ "Imported file _bosch_2018.dbc start";
CM_ "Imported file _bosch_2018.dbc starts
CM_ "Imported file _bosch_2018.dbc star";
CM_ "Imported file _bosch_2018.dbc start
CM_ "Imported file _bosch_2018.dbc start";
CM_ "Imported file _bosch_2018.dbc starts
CM_ "Imported file _bosch_2018.dbc start";
CM_ "Imported file _bosch_2018.dbc starts
CM_ "Imported file _bosch_2018.dbc start";
CM_ "Imported file _bosch_2018.dbc starts
CM_ "Imported file _bosch_2018.dbc starts";
CM_ "Imported file _bosch_2018.dbc starts 
CM_ "Imported file _bosch_2018.dbc starts ";
CM_ "Imported file _bosch_2018.dbc starts h
CM_ "Imported file _bosch_2018.dbc sta";
CM_ "Imported file _bosch_2018.dbc star
CM_ "Imported file _bosch_2018.dbc star";
CM_ "Imported file _bosch_2018.dbc start
CM_ "Imported file _bosch_2018.dbc star";
CM_ "Imported file _bosch_2018.dbc start
CM_ "Imported file _bosch_2018.dbc start";
CM_ "Imported file _bosch_2018.dbc starts
CM_ "Imported file _bosch_2018.dbc sta";
CM_ "Imported file _bosch_2018.dbc star
CM_ "Imported file _bosch_2018.dbc star";
CM_ "Imported file _bosch_2018.dbc start
CM_ "Imported file _bosch_2018.dbc star";
CM_ "Imported file _bosch_2018.dbc start
CM_ "Imported file _bosch_2018.dbc start";
CM_ "Imported file _bosch_2018.dbc starts
CM_ "Imported file _bosch_2018.dbc star";
CM_ "Imported file _bosch_2018.dbc start
CM_ "Imported file _bosch_2018.dbc start";
CM_ "Imported file _bosch_2018.dbc starts
CM_ "Imported file _bosch_2018.dbc star";
CM_ "Imported file _bosch_2018.dbc start
CM_ "Imported file _bosch_2018.dbc start";
CM_ "Imported file _bosch_2018.dbc starts
CM_ "Imported file _bosch_2018.dbc start";
CM_ "Imported file _bosch_2018.dbc starts
CM_ "Imported file _bosch_2018.dbc start";
CM_ "Imported file _bosch_2018.dbc starts
CM_ "Imported file _bosch_2018.dbc starts";
CM_ "Imported file _bosch_2018.dbc starts 
CM_ "Imported file _bosch_2018.dbc starts ";
CM_ "Imported file _bosch_2018.dbc starts h
CM_ "Imported file _bosch_2018.dbc star";
CM_ "Imported file _bosch_2018.dbc start
CM_ "Imported file _bosch_2018.dbc start";
CM_ "Imported file _bosch_2018.dbc starts
CM_ "Imported file _bosch_2018.dbc star";
CM_ "Imported file _bosch_2018.dbc start
CM_ "Imported file _bosch_2018.dbc start";
CM_ "Imported file _bosch_2018.dbc starts
CM_ "Imported file _bosch_2018.dbc start";
CM_ "Imported file _bosch_2018.dbc starts
CM_ "Imported file _bosch_2018.dbc start";
CM_ "Imported file _bosch_2018.dbc starts
CM_ "Imported file _bosch_2018.dbc starts";
CM_ "Imported file _bosch_2018.dbc starts 
CM_ "Imported file _bosch_2018.dbc starts ";
CM_ "Imported file _bosch_2018.dbc starts h
CM_ "Imported file _bosch_2018.dbc start";
CM_ "Imported file _bosch_2018.dbc starts
CM_ "Imported file _bosch_2018.dbc start";
CM_ "Imported file _bosch_2018.dbc starts
CM_ "Imported file _bosch_2018.dbc starts";
CM_ "Imported file _bosch_2018.dbc starts 
CM_ "Imported file _bosch_2018.dbc starts ";
CM_ "Imported file _bosch_2018.dbc starts h
CM_ "Imported file _bosch_2018.dbc starts";
CM_ "Imported file _bosch_2018.dbc starts 
CM_ "Imported file _bosch_2018.dbc starts ";
CM_ "Imported file _bosch_2018.dbc starts h
CM_ "Imported file _bosch_2018.dbc starts ";
CM_ "Imported file _bosch_2018.dbc starts h
CM_ "Imported file _bosch_2018.dbc starts h";
CM_ "Imported file _bosch_2018.dbc starts he
CM_ "Imported file _bosch_2018.dbc sta";
CM_ "Imported file _bosch_2018.dbc star
CM_ "Imported file _bosch_2018.dbc star";
CM_ "Imported file _bosch_2018.dbc start
CM_ "Imported file _bosch_2018.dbc star";
CM_ "Imported file _bosch_2018.dbc start
CM_ "Imported file _bosch_2018.dbc start";
CM_ "Imported file _bosch_2018.dbc starts
CM_ "Imported file _bosch_2018.dbc sta";
CM_ "Imported file _bosch_2018.dbc star
CM_ "Imported file _bosch_2018.dbc star";
CM_ "Imported file _bosch_2018.dbc start
CM_ "Imported file _bosch_2018.dbc star";
CM_ "Imported file _bosch_2018.dbc start
CM_ "Imported file _bosch_2018.dbc start";
CM_ "Imported file _bosch_2018.dbc starts
CM_ "Imported file _bosch_2018.dbc star";
CM_ "Imported file _bosch_2018.dbc start
CM_ "Imported file _bosch_2018.dbc start";
CM_ "Imported file _bosch_2018.dbc starts
CM_ "Imported file _bosch_2018.dbc star";
CM_ "Imported file _bosch_2018.dbc start
CM_ "Imported file _bosch_2018.dbc start";
CM_ "Imported file _bosch_2018.dbc starts
CM_ "Imported file _bosch_2018.dbc start";
CM_ "Imported file _bosch_2018.dbc starts
CM_ "Imported file _bosch_2018.dbc start";
CM_ "Imported file _bosch_2018.dbc starts
CM_ "Imported file _bosch_2018.dbc starts";
CM_ "Imported file _bosch_2018.dbc starts 
CM_ "Imported file _bosch_2018.dbc starts ";
CM_ "Imported file _bosch_2018.dbc starts h
CM_ "Imported file _bosch_2018.dbc star";
CM_ "Imported file _bosch_2018.dbc start
CM_ "Imported file _bosch_2018.dbc start";
CM_ "Imported file _bosch_2018.dbc starts
CM_ "Imported file _bosch_2018.dbc star";
CM_ "Imported file _bosch_2018.dbc start
CM_ "Imported file _bosch_2018.dbc start";
CM_ "Imported file _bosch_2018.dbc starts
CM_ "Imported file _bosch_2018.dbc start";
CM_ "Imported file _bosch_2018.dbc starts
CM_ "Imported file _bosch_2018.dbc start";
CM_ "Imported file _bosch_2018.dbc starts
CM_ "Imported file _bosch_2018.dbc starts";
CM_ "Imported file _bosch_2018.dbc starts 
CM_ "Imported file _bosch_2018.dbc starts ";
CM_ "Imported file _bosch_2018.dbc starts h
CM_ "Imported file _bosch_2018.dbc start";
CM_ "Imported file _bosch_2018.dbc starts
CM_ "Imported file _bosch_2018.dbc start";
CM_ "Imported file _bosch_2018.dbc starts
CM_ "Imported file _bosch_2018.dbc starts";
CM_ "Imported file _bosch_2018.dbc starts 
CM_ "Imported file _bosch_2018.dbc starts ";
CM_ "Imported file _bosch_2018.dbc starts h
CM_ "Imported file _bosch_2018.dbc starts";
CM_ "Imported file _bosch_2018.dbc starts 
CM_ "Imported file _bosch_2018.dbc starts ";
CM_ "Imported file _bosch_2018.dbc starts h
CM_ "Imported file _bosch_2018.dbc starts ";
CM_ "Imported file _bosch_2018.dbc starts h
CM_ "Imported file _bosch_2018.dbc starts h";
CM_ "Imported file _bosch_2018.dbc starts he
CM_ "Imported file _bosch_2018.dbc star";
CM_ "Imported file _bosch_2018.dbc start
CM_ "Imported file _bosch_2018.dbc start";
CM_ "Imported file _bosch_2018.dbc starts
CM_ "Imported file _bosch_2018.dbc star";
CM_ "Imported file _bosch_2018.dbc start
CM_ "Imported file _bosch_2018.dbc start";
CM_ "Imported file _bosch_2018.dbc starts
CM_ "Imported file _bosch_2018.dbc start";
CM_ "Imported file _bosch_2018.dbc starts
CM_ "Imported file _bosch_2018.dbc start";
CM_ "Imported file _bosch_2018.dbc starts
CM_ "Imported file _bosch_2018.dbc starts";
CM_ "Imported file _bosch_2018.dbc starts 
CM_ "Imported file _bosch_2018.dbc starts ";
CM_ "Imported file _bosch_2018.dbc starts h
CM_ "Imported file _bosch_2018.dbc start";
CM_ "Imported file _bosch_2018.dbc starts
CM_ "Imported file _bosch_2018.dbc start";
CM_ "Imported file _bosch_2018.dbc starts
CM_ "Imported file _bosch_2018.dbc starts";
CM_ "Imported file _bosch_2018.dbc starts 
CM_ "Imported file _bosch_2018.dbc starts ";
CM_ "Imported file _bosch_2018.dbc starts h
CM_ "Imported file _bosch_2018.dbc starts";
CM_ "Imported file _bosch_2018.dbc starts 
CM_ "Imported file _bosch_2018.dbc starts ";
CM_ "Imported file _bosch_2018.dbc starts h
CM_ "Imported file _bosch_2018.dbc starts ";
CM_ "Imported file _bosch_2018.dbc starts h
CM_ "Imported file _bosch_2018.dbc starts h";
CM_ "Imported file _bosch_2018.dbc starts he
CM_ "Imported file _bosch_2018.dbc start";
CM_ "Imported file _bosch_2018.dbc starts
CM_ "Imported file _bosch_2018.dbc start";
CM_ "Imported file _bosch_2018.dbc starts
CM_ "Imported file _bosch_2018.dbc starts";
CM_ "Imported file _bosch_2018.dbc starts 
CM_ "Imported file _bosch_2018.dbc starts ";
CM_ "Imported file _bosch_2018.dbc starts h
CM_ "Imported file _bosch_2018.dbc starts";
CM_ "Imported file _bosch_2018.dbc starts 
CM_ "Imported file _bosch_2018.dbc starts ";
CM_ "Imported file _bosch_2018.dbc starts h
CM_ "Imported file _bosch_2018.dbc starts ";
CM_ "Imported file _bosch_2018.dbc starts h
CM_ "Imported file _bosch_2018.dbc starts h";
CM_ "Imported file _bosch_2018.dbc starts he
CM_ "Imported file _bosch_2018.dbc starts";
CM_ "Imported file _bosch_2018.dbc starts 
CM_ "Imported file _bosch_2018.dbc starts ";
CM_ "Imported file _bosch_2018.dbc starts h
CM_ "Imported file _bosch_2018.dbc starts ";
CM_ "Imported file _bosch_2018.dbc starts h
CM_ "Imported file _bosch_2018.dbc starts h";
CM_ "Imported file _bosch_2018.dbc starts he
CM_ "Imported file _bosch_2018.dbc starts ";
CM_ "Imported file _bosch_2018.dbc starts h
CM_ "Imported file _bosch_2018.dbc starts h";
CM_ "Imported file _bosch_2018.dbc starts he
CM_ "Imported file _bosch_2018.dbc starts h";
CM_ "Imported file _bosch_2018.dbc starts he
CM_ "Imported file _bosch_2018.dbc starts he";
CM_ "Imported file _bosch_2018.dbc starts her
CM_ "Imported file _bosch_2018.dbc st";
CM_ "Imported file _bosch_2018.dbc sta
CM_ "Imported file _bosch_2018.dbc sta";
CM_ "Imported file _bosch_2018.dbc star
CM_ "Imported file _bosch_2018.dbc sta";
CM_ "Imported file _bosch_2018.dbc star
CM_ "Imported file _bosch_2018.dbc star";
CM_ "Imported file _bosch_2018.dbc start
CM_ "Imported file _bosch_2018.dbc sta";
CM_ "Imported file _bosch_2018.dbc star
CM_ "Imported file _bosch_2018.dbc star";
CM_ "Imported file _bosch_2018.dbc start
CM_ "Imported file _bosch_2018.dbc star";
CM_ "Imported file _bosch_2018.dbc start
CM_ "Imported file _bosch_2018.dbc start";
CM_ "Imported file _bosch_2018.dbc starts
CM_ "Imported file _bosch_2018.dbc st";
CM_ "Imported file _bosch_2018.dbc sta
CM_ "Imported file _bosch_2018.dbc sta";
CM_ "Imported file _bosch_2018.dbc star
CM_ "Imported file _bosch_2018.dbc sta";
CM_ "Imported file _bosch_2018.dbc star
CM_ "Imported file _bosch_2018.dbc star";
CM_ "Imported file _bosch_2018.dbc start
CM_ "Imported file _bosch_2018.dbc sta";
CM_ "Imported file _bosch_2018.dbc star
CM_ "Imported file _bosch_2018.dbc star";
CM_ "Imported file _bosch_2018.dbc start
CM_ "Imported file _bosch_2018.dbc star";
CM_ "Imported file _bosch_2018.dbc start
CM_ "Imported file _bosch_2018.dbc start";
CM_ "Imported file _bosch_2018.dbc starts
CM_ "Imported file _bosch_2018.dbc sta";
CM_ "Imported file _bosch_2018.dbc star
CM_ "Imported file _bosch_2018.dbc star";
CM_ "Imported file _bosch_2018.dbc start
CM_ "Imported file _bosch_2018.dbc star";
CM_ "Imported file _bosch_2018.dbc start
CM_ "Imported file _bosch_2018.dbc start";
CM_ "Imported file _bosch_2018.dbc starts
CM_ "Imported file _bosch_2018.dbc sta";
CM_ "Imported file _bosch_2018.dbc star
CM_ "Imported file _bosch_2018.dbc star";
CM_ "Imported file _bosch_2018.dbc start
CM_ "Imported file _bosch_2018.dbc star";
CM_ "Imported file _bosch_2018.dbc start
CM_ "Imported file _bosch_2018.dbc start";
CM_ "Imported file _bosch_2018.dbc starts
CM_ "Imported file _bosch_2018.dbc star";
CM_ "Imported file _bosch_2018.dbc start
CM_ "Imported file _bosch_2018.dbc start";
CM_ "Imported file _bosch_2018.dbc starts
CM_ "Imported file _bosch_2018.dbc star";
CM_ "Imported file _bosch_2018.dbc start
CM_ "Imported file _bosch_2018.dbc start";
CM_ "Imported file _bosch_2018.dbc starts
CM_ "Imported file _bosch_2018.dbc start";
CM_ "Imported file _bosch_2018.dbc starts
CM_ "Imported file _bosch_2018.dbc start";
CM_ "Imported file _bosch_2018.dbc starts
CM_ "Imported file _bosch_2018.dbc starts";
CM_ "Imported file _bosch_2018.dbc starts 
CM_ "Imported file _bosch_2018.dbc starts ";
CM_ "Imported file _bosch_2018.dbc starts h
CM_ "Imported file _bosch_2018.dbc sta";
CM_ "Imported file _bosch_2018.dbc star
CM_ "Imported file _bosch_2018.dbc star";
CM_ "Imported file _bosch_2018.dbc start
CM_ "Imported file _bosch_2018.dbc star";
CM_ "Imported file _bosch_2018.dbc start
CM_ "Imported file _bosch_2018.dbc start";
CM_ "Imported file _bosch_2018.dbc starts
CM_ "Imported file _bosch_2018.dbc sta";
CM_ "Imported file _bosch_2018.dbc star
CM_ "Imported file _bosch_2018.dbc star";
CM_ "Imported file _bosch_2018.dbc start
CM_ "Imported file _bosch_2018.dbc star";
CM_ "Imported file _bosch_2018.dbc start
CM_ "Imported file _bosch_2018.dbc start";
CM_ "Imported file _bosch_2018.dbc starts
CM_ "Imported file _bosch_2018.dbc star";
CM_ "Imported file _bosch_2018.dbc start
CM_ "Imported file _bosch_2018.dbc start";
CM_ "Imported file _bosch_2018.dbc starts
CM_ "Imported file _bosch_2018.dbc star";
CM_ "Imported file _bosch_2018.dbc start
CM_ "Imported file _bosch_2018.dbc start";
CM_ "Imported file _bosch_2018.dbc starts
CM_ "Imported file _bosch_2018.dbc start";
CM_ "Imported file _bosch_2018.dbc starts
CM_ "Imported file _bosch_2018.dbc start";
CM_ "Imported file _bosch_2018.dbc starts
CM_ "Imported file _bosch_2018.dbc starts";
CM_ "Imported file _bosch_2018.dbc starts 
CM_ "Imported file _bosch_2018.dbc starts ";
CM_ "Imported file _bosch_2018.dbc starts h
CM_ "Imported file _bosch_2018.dbc star";
CM_ "Imported file _bosch_2018.dbc start
CM_ "Imported file _bosch_2018.dbc start";
CM_ "Imported file _bosch_2018.dbc starts
CM_ "Imported file _bosch_2018.dbc star";
CM_ "Imported file _bosch_2018.dbc start
CM_ "Imported file _bosch_2018.dbc start";
CM_ "Imported file _bosch_2018.dbc starts
CM_ "Imported file _bosch_2018.dbc start";
CM_ "Imported file _bosch_2018.dbc starts
CM_ "Imported file _bosch_2018.dbc start";
CM_ "Imported file _bosch_2018.dbc starts
CM_ "Imported file _bosch_2018.dbc starts";
CM_ "Imported file _bosch_2018.dbc starts 
CM_ "Imported file _bosch_2018.dbc starts ";
CM_ "Imported file _bosch_2018.dbc starts h
CM_ "Imported file _bosch_2018.dbc start";
CM_ "Imported file _bosch_2018.dbc starts
CM_ "Imported file _bosch_2018.dbc start";
CM_ "Imported file _bosch_2018.dbc starts
CM_ "Imported file _bosch_2018.dbc starts";
CM_ "Imported file _bosch_2018.dbc starts 
CM_ "Imported file _bosch_2018.dbc starts ";
CM_ "Imported file _bosch_2018.dbc starts h
CM_ "Imported file _bosch_2018.dbc starts";
CM_ "Imported file _bosch_2018.dbc starts 
CM_ "Imported file _bosch_2018.dbc starts ";
CM_ "Imported file _bosch_2018.dbc starts h
CM_ "Imported file _bosch_2018.dbc starts ";
CM_ "Imported file _bosch_2018.dbc starts h
CM_ "Imported file _bosch_2018.dbc starts h";
CM_ "Imported file _bosch_2018.dbc starts he
CM_ "Imported file _bosch_2018.dbc sta";
CM_ "Imported file _bosch_2018.dbc star
CM_ "Imported file _bosch_2018.dbc star";
CM_ "Imported file _bosch_2018.dbc start
CM_ "Imported file _bosch_2018.dbc star";
CM_ "Imported file _bosch_2018.dbc start
CM_ "Imported file _bosch_2018.dbc start";
CM_ "Imported file _bosch_2018.dbc starts
CM_ "Imported file _bosch_2018.dbc sta";
CM_ "Imported file _bosch_2018.dbc star
CM_ "Imported file _bosch_2018.dbc star";
CM_ "Imported file _bosch_2018.dbc start
CM_ "Imported file _bosch_2018.dbc star";
CM_ "Imported file _bosch_2018.dbc start
CM_ "Imported file _bosch_2018.dbc start";
CM_ "Imported file _bosch_2018.dbc starts
CM_ "Imported file _bosch_2018.dbc star";
CM_ "Imported file _bosch_2018.dbc start
CM_ "Imported file _bosch_2018.dbc start";
CM_ "Imported file _bosch_2018.dbc starts
CM_ "Imported file _bosch_2018.dbc star";
CM_ "Imported file _bosch_2018.dbc start
CM_ "Imported file _bosch_2018.dbc start";
CM_ "Imported file _bosch_2018.dbc starts
CM_ "Imported file _bosch_2018.dbc start";
CM_ "Imported file _bosch_2018.dbc starts
CM_ "Imported file _bosch_2018.dbc start";
CM_ "Imported file _bosch_2018.dbc starts
CM_ "Imported file _bosch_2018.dbc starts";
CM_ "Imported file _bosch_2018.dbc starts 
CM_ "Imported file _bosch_2018.dbc starts ";
CM_ "Imported file _bosch_2018.dbc starts h
CM_ "Imported file _bosch_2018.dbc star";
CM_ "Imported file _bosch_2018.dbc start
CM_ "Imported file _bosch_2018.dbc start";
CM_ "Imported file _bosch_2018.dbc starts
CM_ "Imported file _bosch_2018.dbc star";
CM_ "Imported file _bosch_2018.dbc start
CM_ "Imported file _bosch_2018.dbc start";
CM_ "Imported file _bosch_2018.dbc starts
CM_ "Imported file _bosch_2018.dbc start";
CM_ "Imported file _bosch_2018.dbc starts
CM_ "Imported file _bosch_2018.dbc start";
CM_ "Imported file _bosch_2018.dbc starts
CM_ "Imported file _bosch_2018.dbc starts";
CM_ "Imported file _bosch_2018.dbc starts 
CM_ "Imported file _bosch_2018.dbc starts ";
CM_ "Imported file _bosch_2018.dbc starts h
CM_ "Imported file _bosch_2018.dbc start";
CM_ "Imported file _bosch_2018.dbc starts
CM_ "Imported file _bosch_2018.dbc start";
CM_ "Imported file _bosch_2018.dbc starts
CM_ "Imported file _bosch_2018.dbc starts";
CM_ "Imported file _bosch_2018.dbc starts 
CM_ "Imported file _bosch_2018.dbc starts ";
CM_ "Imported file _bosch_2018.dbc starts h
CM_ "Imported file _bosch_2018.dbc starts";
CM_ "Imported file _bosch_2018.dbc starts 
CM_ "Imported file _bosch_2018.dbc starts ";
CM_ "Imported file _bosch_2018.dbc starts h
CM_ "Imported file _bosch_2018.dbc starts ";
CM_ "Imported file _bosch_2018.dbc starts h
CM_ "Imported file _bosch_2018.dbc starts h";
CM_ "Imported file _bosch_2018.dbc starts he
CM_ "Imported file _bosch_2018.dbc star";
CM_ "Imported file _bosch_2018.dbc start
CM_ "Imported file _bosch_2018.dbc start";
CM_ "Imported file _bosch_2018.dbc starts
CM_ "Imported file _bosch_2018.dbc star";
CM_ "Imported file _bosch_2018.dbc start
CM_ "Imported file _bosch_2018.dbc start";
CM_ "Imported file _bosch_2018.dbc starts
CM_ "Imported file _bosch_2018.dbc start";
CM_ "Imported file _bosch_2018.dbc starts
CM_ "Imported file _bosch_2018.dbc start";
CM_ "Imported file _bosch_2018.dbc starts
CM_ "Imported file _bosch_2018.dbc starts";
CM_ "Imported file _bosch_2018.dbc starts 
CM_ "Imported file _bosch_2018.dbc starts ";
CM_ "Imported file _bosch_2018.dbc starts h
CM_ "Imported file _bosch_2018.dbc start";
CM_ "Imported file _bosch_2018.dbc starts
CM_ "Imported file _bosch_2018.dbc start";
CM_ "Imported file _bosch_2018.dbc starts
CM_ "Imported file _bosch_2018.dbc starts";
CM_ "Imported file _bosch_2018.dbc starts 
CM_ "Imported file _bosch_2018.dbc starts ";
CM_ "Imported file _bosch_2018.dbc starts h
CM_ "Imported file _bosch_2018.dbc starts";
CM_ "Imported file _bosch_2018.dbc starts 
CM_ "Imported file _bosch_2018.dbc starts ";
CM_ "Imported file _bosch_2018.dbc starts h
CM_ "Imported file _bosch_2018.dbc starts ";
CM_ "Imported file _bosch_2018.dbc starts h
CM_ "Imported file _bosch_2018.dbc starts h";
CM_ "Imported file _bosch_2018.dbc starts he
CM_ "Imported file _bosch_2018.dbc start";
CM_ "Imported file _bosch_2018.dbc starts
CM_ "Imported file _bosch_2018.dbc start";
CM_ "Imported file _bosch_2018.dbc starts
CM_ "Imported file _bosch_2018.dbc starts";
CM_ "Imported file _bosch_2018.dbc starts 
CM_ "Imported file _bosch_2018.dbc starts ";
CM_ "Imported file _bosch_2018.dbc starts h
CM_ "Imported file _bosch_2018.dbc starts";
CM_ "Imported file _bosch_2018.dbc starts 
CM_ "Imported file _bosch_2018.dbc starts ";
CM_ "Imported file _bosch_2018.dbc starts h
CM_ "Imported file _bosch_2018.dbc starts ";
CM_ "Imported file _bosch_2018.dbc starts h
CM_ "Imported file _bosch_2018.dbc starts h";
CM_ "Imported file _bosch_2018.dbc starts he
CM_ "Imported file _bosch_2018.dbc starts";
CM_ "Imported file _bosch_2018.dbc starts 
CM_ "Imported file _bosch_2018.dbc starts ";
CM_ "Imported file _bosch_2018.dbc starts h
CM_ "Imported file _bosch_2018.dbc starts ";
CM_ "Imported file _bosch_2018.dbc starts h
CM_ "Imported file _bosch_2018.dbc starts h";
CM_ "Imported file _bosch_2018.dbc starts he
CM_ "Imported file _bosch_2018.dbc starts ";
CM_ "Imported file _bosch_2018.dbc starts h
CM_ "Imported file _bosch_2018.dbc starts h";
CM_ "Imported file _bosch_2018.dbc starts he
CM_ "Imported file _bosch_2018.dbc starts h";
CM_ "Imported file _bosch_2018.dbc starts he
CM_ "Imported file _bosch_2018.dbc starts he";
CM_ "Imported file _bosch_2018.dbc starts her
CM_ "Imported file _bosch_2018.dbc sta";
CM_ "Imported file _bosch_2018.dbc star
CM_ "Imported file _bosch_2018.dbc star";
CM_ "Imported file _bosch_2018.dbc start
CM_ "Imported file _bosch_2018.dbc star";
CM_ "Imported file _bosch_2018.dbc start
CM_ "Imported file _bosch_2018.dbc start";
CM_ "Imported file _bosch_2018.dbc starts
CM_ "Imported file _bosch_2018.dbc sta";
CM_ "Imported file _bosch_2018.dbc star
CM_ "Imported file _bosch_2018.dbc star";
CM_ "Imported file _bosch_2018.dbc start
CM_ "Imported file _bosch_2018.dbc star";
CM_ "Imported file _bosch_2018.dbc start
CM_ "Imported file _bosch_2018.dbc start";
CM_ "Imported file _bosch_2018.dbc starts
CM_ "Imported file _bosch_2018.dbc star";
CM_ "Imported file _bosch_2018.dbc start
CM_ "Imported file _bosch_2018.dbc start";
CM_ "Imported file _bosch_2018.dbc starts
CM_ "Imported file _bosch_2018.dbc star";
CM_ "Imported file _bosch_2018.dbc start
CM_ "Imported file _bosch_2018.dbc start";
CM_ "Imported file _bosch_2018.dbc starts
CM_ "Imported file _bosch_2018.dbc start";
CM_ "Imported file _bosch_2018.dbc starts
CM_ "Imported file _bosch_2018.dbc start";
CM_ "Imported file _bosch_2018.dbc starts
CM_ "Imported file _bosch_2018.dbc starts";
CM_ "Imported file _bosch_2018.dbc starts 
CM_ "Imported file _bosch_2018.dbc starts ";
CM_ "Imported file _bosch_2018.dbc starts h
CM_ "Imported file _bosch_2018.dbc star";
CM_ "Imported file _bosch_2018.dbc start
CM_ "Imported file _bosch_2018.dbc start";
CM_ "Imported file _bosch_2018.dbc starts
CM_ "Imported file _bosch_2018.dbc star";
CM_ "Imported file _bosch_2018.dbc start
CM_ "Imported file _bosch_2018.dbc start";
CM_ "Imported file _bosch_2018.dbc starts
CM_ "Imported file _bosch_2018.dbc start";
CM_ "Imported file _bosch_2018.dbc starts
CM_ "Imported file _bosch_2018.dbc start";
CM_ "Imported file _bosch_2018.dbc starts
CM_ "Imported file _bosch_2018.dbc starts";
CM_ "Imported file _bosch_2018.dbc starts 
CM_ "Imported file _bosch_2018.dbc starts ";
CM_ "Imported file _bosch_2018.dbc starts h
CM_ "Imported file _bosch_2018.dbc start";
CM_ "Imported file _bosch_2018.dbc starts
CM_ "Imported file _bosch_2018.dbc start";
CM_ "Imported file _bosch_2018.dbc starts
CM_ "Imported file _bosch_2018.dbc starts";
CM_ "Imported file _bosch_2018.dbc starts 
CM_ "Imported file _bosch_2018.dbc starts ";
CM_ "Imported file _bosch_2018.dbc starts h
CM_ "Imported file _bosch_2018.dbc starts";
CM_ "Imported file _bosch_2018.dbc starts 
CM_ "Imported file _bosch_2018.dbc starts ";
CM_ "Imported file _bosch_2018.dbc starts h
CM_ "Imported file _bosch_2018.dbc starts ";
CM_ "Imported file _bosch_2018.dbc starts h
CM_ "Imported file _bosch_2018.dbc starts h";
CM_ "Imported file _bosch_2018.dbc starts he
CM_ "Imported file _bosch_2018.dbc star";
CM_ "Imported file _bosch_2018.dbc start
CM_ "Imported file _bosch_2018.dbc start";
CM_ "Imported file _bosch_2018.dbc starts
CM_ "Imported file _bosch_2018.dbc star";
CM_ "Imported file _bosch_2018.dbc start
CM_ "Imported file _bosch_2018.dbc start";
CM_ "Imported file _bosch_2018.dbc starts
CM_ "Imported file _bosch_2018.dbc start";
CM_ "Imported file _bosch_2018.dbc starts
CM_ "Imported file _bosch_2018.dbc start";
CM_ "Imported file _bosch_2018.dbc starts
CM_ "Imported file _bosch_2018.dbc starts";
CM_ "Imported file _bosch_2018.dbc starts 
CM_ "Imported file _bosch_2018.dbc starts ";
CM_ "Imported file _bosch_2018.dbc starts h
CM_ "Imported file _bosch_2018.dbc start";
CM_ "Imported file _bosch_2018.dbc starts
CM_ "Imported file _bosch_2018.dbc start";
CM_ "Imported file _bosch_2018.dbc starts
CM_ "Imported file _bosch_2018.dbc starts";
CM_ "Imported file _bosch_2018.dbc starts 
CM_ "Imported file _bosch_2018.dbc starts ";
CM_ "Imported file _bosch_2018.dbc starts h
CM_ "Imported file _bosch_2018.dbc starts";
CM_ "Imported file _bosch_2018.dbc starts 
CM_ "Imported file _bosch_2018.dbc starts ";
CM_ "Imported file _bosch_2018.dbc starts h
CM_ "Imported file _bosch_2018.dbc starts ";
CM_ "Imported file _bosch_2018.dbc starts h
CM_ "Imported file _bosch_2018.dbc starts h";
CM_ "Imported file _bosch_2018.dbc starts he
CM_ "Imported file _bosch_2018.dbc start";
CM_ "Imported file _bosch_2018.dbc starts
CM_ "Imported file _bosch_2018.dbc start";
CM_ "Imported file _bosch_2018.dbc starts
CM_ "Imported file _bosch_2018.dbc starts";
CM_ "Imported file _bosch_2018.dbc starts 
CM_ "Imported file _bosch_2018.dbc starts ";
CM_ "Imported file _bosch_2018.dbc starts h
CM_ "Imported file _bosch_2018.dbc starts";
CM_ "Imported file _bosch_2018.dbc starts 
CM_ "Imported file _bosch_2018.dbc starts ";
CM_ "Imported file _bosch_2018.dbc starts h
CM_ "Imported file _bosch_2018.dbc starts ";
CM_ "Imported file _bosch_2018.dbc starts h
CM_ "Imported file _bosch_2018.dbc starts h";
CM_ "Imported file _bosch_2018.dbc starts he
CM_ "Imported file _bosch_2018.dbc starts";
CM_ "Imported file _bosch_2018.dbc starts 
CM_ "Imported file _bosch_2018.dbc starts ";
CM_ "Imported file _bosch_2018.dbc starts h
CM_ "Imported file _bosch_2018.dbc starts ";
CM_ "Imported file _bosch_2018.dbc starts h
CM_ "Imported file _bosch_2018.dbc starts h";
CM_ "Imported file _bosch_2018.dbc starts he
CM_ "Imported file _bosch_2018.dbc starts ";
CM_ "Imported file _bosch_2018.dbc starts h
CM_ "Imported file _bosch_2018.dbc starts h";
CM_ "Imported file _bosch_2018.dbc starts he
CM_ "Imported file _bosch_2018.dbc starts h";
CM_ "Imported file _bosch_2018.dbc starts he
CM_ "Imported file _bosch_2018.dbc starts he";
CM_ "Imported file _bosch_2018.dbc starts her
CM_ "Imported file _bosch_2018.dbc star";
CM_ "Imported file _bosch_2018.dbc start
CM_ "Imported file _bosch_2018.dbc start";
CM_ "Imported file _bosch_2018.dbc starts
CM_ "Imported file _bosch_2018.dbc star";
CM_ "Imported file _bosch_2018.dbc start
CM_ "Imported file _bosch_2018.dbc start";
CM_ "Imported file _bosch_2018.dbc starts
CM_ "Imported file _bosch_2018.dbc start";
CM_ "Imported file _bosch_2018.dbc starts
CM_ "Imported file _bosch_2018.dbc start";
CM_ "Imported file _bosch_2018.dbc starts
CM_ "Imported file _bosch_2018.dbc starts";
CM_ "Imported file _bosch_2018.dbc starts 
CM_ "Imported file _bosch_2018.dbc starts ";
CM_ "Imported file _bosch_2018.dbc starts h
CM_ "Imported file _bosch_2018.dbc start";
CM_ "Imported file _bosch_2018.dbc starts
CM_ "Imported file _bosch_2018.dbc start";
CM_ "Imported file _bosch_2018.dbc starts
CM_ "Imported file _bosch_2018.dbc starts";
CM_ "Imported file _bosch_2018.dbc starts 
CM_ "Imported file _bosch_2018.dbc starts ";
CM_ "Imported file _bosch_2018.dbc starts h
CM_ "Imported file _bosch_2018.dbc starts";
CM_ "Imported file _bosch_2018.dbc starts 
CM_ "Imported file _bosch_2018.dbc starts ";
CM_ "Imported file _bosch_2018.dbc starts h
CM_ "Imported file _bosch_2018.dbc starts ";
CM_ "Imported file _bosch_2018.dbc starts h
CM_ "Imported file _bosch_2018.dbc starts h";
CM_ "Imported file _bosch_2018.dbc starts he
CM_ "Imported file _bosch_2018.dbc start";
CM_ "Imported file _bosch_2018.dbc starts
CM_ "Imported file _bosch_2018.dbc start";
CM_ "Imported file _bosch_2018.dbc starts
CM_ "Imported file _bosch_2018.dbc starts";
CM_ "Imported file _bosch_2018.dbc starts 
CM_ "Imported file _bosch_2018.dbc starts ";
CM_ "Imported file _bosch_2018.dbc starts h
CM_ "Imported file _bosch_2018.dbc starts";
CM_ "Imported file _bosch_2018.dbc starts 
CM_ "Imported file _bosch_2018.dbc starts ";
CM_ "Imported file _bosch_2018.dbc starts h
CM_ "Imported file _bosch_2018.dbc starts ";
CM_ "Imported file _bosch_2018.dbc starts h
CM_ "Imported file _bosch_2018.dbc starts h";
CM_ "Imported file _bosch_2018.dbc starts he
CM_ "Imported file _bosch_2018.dbc starts";
CM_ "Imported file _bosch_2018.dbc starts 
CM_ "Imported file _bosch_2018.dbc starts ";
CM_ "Imported file _bosch_2018.dbc starts h
CM_ "Imported file _bosch_2018.dbc starts ";
CM_ "Imported file _bosch_2018.dbc starts h
CM_ "Imported file _bosch_2018.dbc starts h";
CM_ "Imported file _bosch_2018.dbc starts he
CM_ "Imported file _bosch_2018.dbc starts ";
CM_ "Imported file _bosch_2018.dbc starts h
CM_ "Imported file _bosch_2018.dbc starts h";
CM_ "Imported file _bosch_2018.dbc starts he
CM_ "Imported file _bosch_2018.dbc starts h";
CM_ "Imported file _bosch_2018.dbc starts he
CM_ "Imported file _bosch_2018.dbc starts he";
CM_ "Imported file _bosch_2018.dbc starts her
CM_ "Imported file _bosch_2018.dbc start";
CM_ "Imported file _bosch_2018.dbc starts
CM_ "Imported file _bosch_2018.dbc start";
CM_ "Imported file _bosch_2018.dbc starts
CM_ "Imported file _bosch_2018.dbc starts";
CM_ "Imported file _bosch_2018.dbc starts 
CM_ "Imported file _bosch_2018.dbc starts ";
CM_ "Imported file _bosch_2018.dbc starts h
CM_ "Imported file _bosch_2018.dbc starts";
CM_ "Imported file _bosch_2018.dbc starts 
CM_ "Imported file _bosch_2018.dbc starts ";
CM_ "Imported file _bosch_2018.dbc starts h
CM_ "Imported file _bosch_2018.dbc starts ";
CM_ "Imported file _bosch_2018.dbc starts h
CM_ "Imported file _bosch_2018.dbc starts h";
CM_ "Imported file _bosch_2018.dbc starts he
CM_ "Imported file _bosch_2018.dbc starts";
CM_ "Imported file _bosch_2018.dbc starts 
CM_ "Imported file _bosch_2018.dbc starts ";
CM_ "Imported file _bosch_2018.dbc starts h
CM_ "Imported file _bosch_2018.dbc starts ";
CM_ "Imported file _bosch_2018.dbc starts h
CM_ "Imported file _bosch_2018.dbc starts h";
CM_ "Imported file _bosch_2018.dbc starts he
CM_ "Imported file _bosch_2018.dbc starts ";
CM_ "Imported file _bosch_2018.dbc starts h
CM_ "Imported file _bosch_2018.dbc starts h";
CM_ "Imported file _bosch_2018.dbc starts he
CM_ "Imported file _bosch_2018.dbc starts h";
CM_ "Imported file _bosch_2018.dbc starts he
CM_ "Imported file _bosch_2018.dbc starts he";
CM_ "Imported file _bosch_2018.dbc starts her
CM_ "Imported file _bosch_2018.dbc starts";
CM_ "Imported file _bosch_2018.dbc starts 
CM_ "Imported file _bosch_2018.dbc starts ";
CM_ "Imported file _bosch_2018.dbc starts h
CM_ "Imported file _bosch_2018.dbc starts ";
CM_ "Imported file _bosch_2018.dbc starts h
CM_ "Imported file _bosch_2018.dbc starts h";
CM_ "Imported file _bosch_2018.dbc starts he
CM_ "Imported file _bosch_2018.dbc starts ";
CM_ "Imported file _bosch_2018.dbc starts h
CM_ "Imported file _bosch_2018.dbc starts h";
CM_ "Imported file _bosch_2018.dbc starts he
CM_ "Imported file _bosch_2018.dbc starts h";
CM_ "Imported file _bosch_2018.dbc starts he
CM_ "Imported file _bosch_2018.dbc starts he";
CM_ "Imported file _bosch_2018.dbc starts her
CM_ "Imported file _bosch_2018.dbc starts ";
CM_ "Imported file _bosch_2018.dbc starts h
CM_ "Imported file _bosch_2018.dbc starts h";
CM_ "Imported file _bosch_2018.dbc starts he
CM_ "Imported file _bosch_2018.dbc starts h";
CM_ "Imported file _bosch_2018.dbc starts he
CM_ "Imported file _bosch_2018.dbc starts he";
CM_ "Imported file _bosch_2018.dbc starts her
CM_ "Imported file _bosch_2018.dbc starts h";
CM_ "Imported file _bosch_2018.dbc starts he
CM_ "Imported file _bosch_2018.dbc starts he";
CM_ "Imported file _bosch_2018.dbc starts her
CM_ "Imported file _bosch_2018.dbc starts he";
CM_ "Imported file _bosch_2018.dbc starts her
CM_ "Imported file _bosch_2018.dbc starts her";
CM_ "Imported file _bosch_2018.dbc starts here
CM_ "Imported file _bosch_2018.dbc st";
CM_ "Imported file _bosch_2018.dbc sta
CM_ "Imported file _bosch_2018.dbc sta";
CM_ "Imported file _bosch_2018.dbc star
CM_ "Imported file _bosch_2018.dbc sta";
CM_ "Imported file _bosch_2018.dbc star
CM_ "Imported file _bosch_2018.dbc star";
CM_ "Imported file _bosch_2018.dbc start
CM_ "Imported file _bosch_2018.dbc sta";
CM_ "Imported file _bosch_2018.dbc star
CM_ "Imported file _bosch_2018.dbc star";
CM_ "Imported file _bosch_2018.dbc start
CM_ "Imported file _bosch_2018.dbc star";
CM_ "Imported file _bosch_2018.dbc start
CM_ "Imported file _bosch_2018.dbc start";
CM_ "Imported file _bosch_2018.dbc starts
CM_ "Imported file _bosch_2018.dbc st";
CM_ "Imported file _bosch_2018.dbc sta
CM_ "Imported file _bosch_2018.dbc sta";
CM_ "Imported file _bosch_2018.dbc star
CM_ "Imported file _bosch_2018.dbc sta";
CM_ "Imported file _bosch_2018.dbc star
CM_ "Imported file _bosch_2018.dbc star";
CM_ "Imported file _bosch_2018.dbc start
CM_ "Imported file _bosch_2018.dbc sta";
CM_ "Imported file _bosch_2018.dbc star
CM_ "Imported file _bosch_2018.dbc star";
CM_ "Imported file _bosch_2018.dbc start
CM_ "Imported file _bosch_2018.dbc star";
CM_ "Imported file _bosch_2018.dbc start
CM_ "Imported file _bosch_2018.dbc start";
CM_ "Imported file _bosch_2018.dbc starts
CM_ "Imported file _bosch_2018.dbc sta";
CM_ "Imported file _bosch_2018.dbc star
CM_ "Imported file _bosch_2018.dbc star";
CM_ "Imported file _bosch_2018.dbc start
CM_ "Imported file _bosch_2018.dbc star";
CM_ "Imported file _bosch_2018.dbc start
CM_ "Imported file _bosch_2018.dbc start";
CM_ "Imported file _bosch_2018.dbc starts
CM_ "Imported file _bosch_2018.dbc sta";
CM_ "Imported file _bosch_2018.dbc star
CM_ "Imported file _bosch_2018.dbc star";
CM_ "Imported file _bosch_2018.dbc start
CM_ "Imported file _bosch_2018.dbc star";
CM_ "Imported file _bosch_2018.dbc start
CM_ "Imported file _bosch_2018.dbc start";
CM_ "Imported file _bosch_2018.dbc starts
CM_ "Imported file _bosch_2018.dbc star";
CM_ "Imported file _bosch_2018.dbc start
CM_ "Imported file _bosch_2018.dbc start";
CM_ "Imported file _bosch_2018.dbc starts
CM_ "Imported file _bosch_2018.dbc star";
CM_ "Imported file _bosch_2018.dbc start
CM_ "Imported file _bosch_2018.dbc start";
CM_ "Imported file _bosch_2018.dbc starts
CM_ "Imported file _bosch_2018.dbc start";
CM_ "Imported file _bosch_2018.dbc starts
CM_ "Imported file _bosch_2018.dbc start";
CM_ "Imported file _bosch_2018.dbc starts
CM_ "Imported file _bosch_2018.dbc starts";
CM_ "Imported file _bosch_2018.dbc starts 
CM_ "Imported file _bosch_2018.dbc starts ";
CM_ "Imported file _bosch_2018.dbc starts h
CM_ "Imported file _bosch_2018.dbc sta";
CM_ "Imported file _bosch_2018.dbc star
CM_ "Imported file _bosch_2018.dbc star";
CM_ "Imported file _bosch_2018.dbc start
CM_ "Imported file _bosch_2018.dbc star";
CM_ "Imported file _bosch_2018.dbc start
CM_ "Imported file _bosch_2018.dbc start";
CM_ "Imported file _bosch_2018.dbc starts
CM_ "Imported file _bosch_2018.dbc sta";
CM_ "Imported file _bosch_2018.dbc star
CM_ "Imported file _bosch_2018.dbc star";
CM_ "Imported file _bosch_2018.dbc start
CM_ "Imported file _bosch_2018.dbc star";
CM_ "Imported file _bosch_2018.dbc start
CM_ "Imported file _bosch_2018.dbc start";
CM_ "Imported file _bosch_2018.dbc starts
CM_ "Imported file _bosch_2018.dbc star";
CM_ "Imported file _bosch_2018.dbc start
CM_ "Imported file _bosch_2018.dbc start";
CM_ "Imported file _bosch_2018.dbc starts
CM_ "Imported file _bosch_2018.dbc star";
CM_ "Imported file _bosch_2018.dbc start
CM_ "Imported file _bosch_2018.dbc start";
CM_ "Imported file _bosch_2018.dbc starts
CM_ "Imported file _bosch_2018.dbc start";
CM_ "Imported file _bosch_2018.dbc starts
CM_ "Imported file _bosch_2018.dbc start";
CM_ "Imported file _bosch_2018.dbc starts
CM_ "Imported file _bosch_2018.dbc starts";
CM_ "Imported file _bosch_2018.dbc starts 
CM_ "Imported file _bosch_2018.dbc starts ";
CM_ "Imported file _bosch_2018.dbc starts h
CM_ "Imported file _bosch_2018.dbc star";
CM_ "Imported file _bosch_2018.dbc start
CM_ "Imported file _bosch_2018.dbc start";
CM_ "Imported file _bosch_2018.dbc starts
CM_ "Imported file _bosch_2018.dbc star";
CM_ "Imported file _bosch_2018.dbc start
CM_ "Imported file _bosch_2018.dbc start";
CM_ "Imported file _bosch_2018.dbc starts
CM_ "Imported file _bosch_2018.dbc start";
CM_ "Imported file _bosch_2018.dbc starts
CM_ "Imported file _bosch_2018.dbc start";
CM_ "Imported file _bosch_2018.dbc starts
CM_ "Imported file _bosch_2018.dbc starts";
CM_ "Imported file _bosch_2018.dbc starts 
CM_ "Imported file _bosch_2018.dbc starts ";
CM_ "Imported file _bosch_2018.dbc starts h
CM_ "Imported file _bosch_2018.dbc start";
CM_ "Imported file _bosch_2018.dbc starts
CM_ "Imported file _bosch_2018.dbc start";
CM_ "Imported file _bosch_2018.dbc starts
CM_ "Imported file _bosch_2018.dbc starts";
CM_ "Imported file _bosch_2018.dbc starts 
CM_ "Imported file _bosch_2018.dbc starts ";
CM_ "Imported file _bosch_2018.dbc starts h
CM_ "Imported file _bosch_2018.dbc starts";
CM_ "Imported file _bosch_2018.dbc starts 
CM_ "Imported file _bosch_2018.dbc starts ";
CM_ "Imported file _bosch_2018.dbc starts h
CM_ "Imported file _bosch_2018.dbc starts ";
CM_ "Imported file _bosch_2018.dbc starts h
CM_ "Imported file _bosch_2018.dbc starts h";
CM_ "Imported file _bosch_2018.dbc starts he
CM_ "Imported file _bosch_2018.dbc sta";
CM_ "Imported file _bosch_2018.dbc star
CM_ "Imported file _bosch_2018.dbc star";
CM_ "Imported file _bosch_2018.dbc start
CM_ "Imported file _bosch_2018.dbc star";
CM_ "Imported file _bosch_2018.dbc start
CM_ "Imported file _bosch_2018.dbc start";
CM_ "Imported file _bosch_2018.dbc starts
CM_ "Imported file _bosch_2018.dbc sta";
CM_ "Imported file _bosch_2018.dbc star
CM_ "Imported file _bosch_2018.dbc star";
CM_ "Imported file _bosch_2018.dbc start
CM_ "Imported file _bosch_2018.dbc star";
CM_ "Imported file _bosch_2018.dbc start
CM_ "Imported file _bosch_2018.dbc start";
CM_ "Imported file _bosch_2018.dbc starts
CM_ "Imported file _bosch_2018.dbc star";
CM_ "Imported file _bosch_2018.dbc start
CM_ "Imported file _bosch_2018.dbc start";
CM_ "Imported file _bosch_2018.dbc starts
CM_ "Imported file _bosch_2018.dbc star";
CM_ "Imported file _bosch_2018.dbc start
CM_ "Imported file _bosch_2018.dbc start";
CM_ "Imported file _bosch_2018.dbc starts
CM_ "Imported file _bosch_2018.dbc start";
CM_ "Imported file _bosch_2018.dbc starts
CM_ "Imported file _bosch_2018.dbc start";
CM_ "Imported file _bosch_2018.dbc starts
CM_ "Imported file _bosch_2018.dbc starts";
CM_ "Imported file _bosch_2018.dbc starts 
CM_ "Imported file _bosch_2018.dbc starts ";
CM_ "Imported file _bosch_2018.dbc starts h
CM_ "Imported file _bosch_2018.dbc star";
CM_ "Imported file _bosch_2018.dbc start
CM_ "Imported file _bosch_2018.dbc start";
CM_ "Imported file _bosch_2018.dbc starts
CM_ "Imported file _bosch_2018.dbc star";
CM_ "Imported file _bosch_2018.dbc start
CM_ "Imported file _bosch_2018.dbc start";
CM_ "Imported file _bosch_2018.dbc starts
CM_ "Imported file _bosch_2018.dbc start";
CM_ "Imported file _bosch_2018.dbc starts
CM_ "Imported file _bosch_2018.dbc start";
CM_ "Imported file _bosch_2018.dbc starts
CM_ "Imported file _bosch_2018.dbc starts";
CM_ "Imported file _bosch_2018.dbc starts 
CM_ "Imported file _bosch_2018.dbc starts ";
CM_ "Imported file _bosch_2018.dbc starts h
CM_ "Imported file _bosch_2018.dbc start";
CM_ "Imported file _bosch_2018.dbc starts
CM_ "Imported file _bosch_2018.dbc start";
CM_ "Imported file _bosch_2018.dbc starts
CM_ "Imported file _bosch_2018.dbc starts";
CM_ "Imported file _bosch_2018.dbc starts 
CM_ "Imported file _bosch_2018.dbc starts ";
CM_ "Imported file _bosch_2018.dbc starts h
CM_ "Imported file _bosch_2018.dbc starts";
CM_ "Imported file _bosch_2018.dbc starts 
CM_ "Imported file _bosch_2018.dbc starts ";
CM_ "Imported file _bosch_2018.dbc starts h
CM_ "Imported file _bosch_2018.dbc starts ";
CM_ "Imported file _bosch_2018.dbc starts h
CM_ "Imported file _bosch_2018.dbc starts h";
CM_ "Imported file _bosch_2018.dbc starts he
CM_ "Imported file _bosch_2018.dbc star";
CM_ "Imported file _bosch_2018.dbc start
CM_ "Imported file _bosch_2018.dbc start";
CM_ "Imported file _bosch_2018.dbc starts
CM_ "Imported file _bosch_2018.dbc star";
CM_ "Imported file _bosch_2018.dbc start
CM_ "Imported file _bosch_2018.dbc start";
CM_ "Imported file _bosch_2018.dbc starts
CM_ "Imported file _bosch_2018.dbc start";
CM_ "Imported file _bosch_2018.dbc starts
CM_ "Imported file _bosch_2018.dbc start";
CM_ "Imported file _bosch_2018.dbc starts
CM_ "Imported file _bosch_2018.dbc starts";
CM_ "Imported file _bosch_2018.dbc starts 
CM_ "Imported file _bosch_2018.dbc starts ";
CM_ "Imported file _bosch_2018.dbc starts h
CM_ "Imported file _bosch_2018.dbc start";
CM_ "Imported file _bosch_2018.dbc starts
CM_ "Imported file _bosch_2018.dbc start";
CM_ "Imported file _bosch_2018.dbc starts
CM_ "Imported file _bosch_2018.dbc starts";
CM_ "Imported file _bosch_2018.dbc starts 
CM_ "Imported file _bosch_2018.dbc starts ";
CM_ "Imported file _bosch_2018.dbc starts h
CM_ "Imported file _bosch_2018.dbc starts";
CM_ "Imported file _bosch_2018.dbc starts 
CM_ "Imported file _bosch_2018.dbc starts ";
CM_ "Imported file _bosch_2018.dbc starts h
CM_ "Imported file _bosch_2018.dbc starts ";
CM_ "Imported file _bosch_2018.dbc starts h
CM_ "Imported file _bosch_2018.dbc starts h";
CM_ "Imported file _bosch_2018.dbc starts he
CM_ "Imported file _bosch_2018.dbc start";
CM_ "Imported file _bosch_2018.dbc starts
CM_ "Imported file _bosch_2018.dbc start";
CM_ "Imported file _bosch_2018.dbc starts
CM_ "Imported file _bosch_2018.dbc starts";
CM_ "Imported file _bosch_2018.dbc starts 
CM_ "Imported file _bosch_2018.dbc starts ";
CM_ "Imported file _bosch_2018.dbc starts h
CM_ "Imported file _bosch_2018.dbc starts";
CM_ "Imported file _bosch_2018.dbc starts 
CM_ "Imported file _bosch_2018.dbc starts ";
CM_ "Imported file _bosch_2018.dbc starts h
CM_ "Imported file _bosch_2018.dbc starts ";
CM_ "Imported file _bosch_2018.dbc starts h
CM_ "Imported file _bosch_2018.dbc starts h";
CM_ "Imported file _bosch_2018.dbc starts he
CM_ "Imported file _bosch_2018.dbc starts";
CM_ "Imported file _bosch_2018.dbc starts 
CM_ "Imported file _bosch_2018.dbc starts ";
CM_ "Imported file _bosch_2018.dbc starts h
CM_ "Imported file _bosch_2018.dbc starts ";
CM_ "Imported file _bosch_2018.dbc starts h
CM_ "Imported file _bosch_2018.dbc starts h";
CM_ "Imported file _bosch_2018.dbc starts he
CM_ "Imported file _bosch_2018.dbc starts ";
CM_ "Imported file _bosch_2018.dbc starts h
CM_ "Imported file _bosch_2018.dbc starts h";
CM_ "Imported file _bosch_2018.dbc starts he
CM_ "Imported file _bosch_2018.dbc starts h";
CM_ "Imported file _bosch_2018.dbc starts he
CM_ "Imported file _bosch_2018.dbc starts he";
CM_ "Imported file _bosch_2018.dbc starts her
CM_ "Imported file _bosch_2018.dbc sta";
CM_ "Imported file _bosch_2018.dbc star
CM_ "Imported file _bosch_2018.dbc star";
CM_ "Imported file _bosch_2018.dbc start
CM_ "Imported file _bosch_2018.dbc star";
CM_ "Imported file _bosch_2018.dbc start
CM_ "Imported file _bosch_2018.dbc start";
CM_ "Imported file _bosch_2018.dbc starts
CM_ "Imported file _bosch_2018.dbc sta";
CM_ "Imported file _bosch_2018.dbc star
CM_ "Imported file _bosch_2018.dbc star";
CM_ "Imported file _bosch_2018.dbc start
CM_ "Imported file _bosch_2018.dbc star";
CM_ "Imported file _bosch_2018.dbc start
CM_ "Imported file _bosch_2018.dbc start";
CM_ "Imported file _bosch_2018.dbc starts
CM_ "Imported file _bosch_2018.dbc star";
CM_ "Imported file _bosch_2018.dbc start
CM_ "Imported file _bosch_2018.dbc start";
CM_ "Imported file _bosch_2018.dbc starts
CM_ "Imported file _bosch_2018.dbc star";
CM_ "Imported file _bosch_2018.dbc start
CM_ "Imported file _bosch_2018.dbc start";
CM_ "Imported file _bosch_2018.dbc starts
CM_ "Imported file _bosch_2018.dbc start";
CM_ "Imported file _bosch_2018.dbc starts
CM_ "Imported file _bosch_2018.dbc start";
CM_ "Imported file _bosch_2018.dbc starts
CM_ "Imported file _bosch_2018.dbc starts";
CM_ "Imported file _bosch_2018.dbc starts 
CM_ "Imported file _bosch_2018.dbc starts ";
CM_ "Imported file _bosch_2018.dbc starts h
CM_ "Imported file _bosch_2018.dbc star";
CM_ "Imported file _bosch_2018.dbc start
CM_ "Imported file _bosch_2018.dbc start";
CM_ "Imported file _bosch_2018.dbc starts
CM_ "Imported file _bosch_2018.dbc star";
CM_ "Imported file _bosch_2018.dbc start
CM_ "Imported file _bosch_2018.dbc start";
CM_ "Imported file _bosch_2018.dbc starts
CM_ "Imported file _bosch_2018.dbc start";
CM_ "Imported file _bosch_2018.dbc starts
CM_ "Imported file _bosch_2018.dbc start";
CM_ "Imported file _bosch_2018.dbc starts
CM_ "Imported file _bosch_2018.dbc starts";
CM_ "Imported file _bosch_2018.dbc starts 
CM_ "Imported file _bosch_2018.dbc starts ";
CM_ "Imported file _bosch_2018.dbc starts h
CM_ "Imported file _bosch_2018.dbc start";
CM_ "Imported file _bosch_2018.dbc starts
CM_ "Imported file _bosch_2018.dbc start";
CM_ "Imported file _bosch_2018.dbc starts
CM_ "Imported file _bosch_2018.dbc starts";
CM_ "Imported file _bosch_2018.dbc starts 
CM_ "Imported file _bosch_2018.dbc starts ";
CM_ "Imported file _bosch_2018.dbc starts h
CM_ "Imported file _bosch_2018.dbc starts";
CM_ "Imported file _bosch_2018.dbc starts 
CM_ "Imported file _bosch_2018.dbc starts ";
CM_ "Imported file _bosch_2018.dbc starts h
CM_ "Imported file _bosch_2018.dbc starts ";
CM_ "Imported file _bosch_2018.dbc starts h
CM_ "Imported file _bosch_2018.dbc starts h";
CM_ "Imported file _bosch_2018.dbc starts he
CM_ "Imported file _bosch_2018.dbc star";
CM_ "Imported file _bosch_2018.dbc start
CM_ "Imported file _bosch_2018.dbc start";
CM_ "Imported file _bosch_2018.dbc starts
CM_ "Imported file _bosch_2018.dbc star";
CM_ "Imported file _bosch_2018.dbc start
CM_ "Imported file _bosch_2018.dbc start";
CM_ "Imported file _bosch_2018.dbc starts
CM_ "Imported file _bosch_2018.dbc start";
CM_ "Imported file _bosch_2018.dbc starts
CM_ "Imported file _bosch_2018.dbc start";
CM_ "Imported file _bosch_2018.dbc starts
CM_ "Imported file _bosch_2018.dbc starts";
CM_ "Imported file _bosch_2018.dbc starts 
CM_ "Imported file _bosch_2018.dbc starts ";
CM_ "Imported file _bosch_2018.dbc starts h
CM_ "Imported file _bosch_2018.dbc start";
CM_ "Imported file _bosch_2018.dbc starts
CM_ "Imported file _bosch_2018.dbc start";
CM_ "Imported file _bosch_2018.dbc starts
CM_ "Imported file _bosch_2018.dbc starts";
CM_ "Imported file _bosch_2018.dbc starts 
CM_ "Imported file _bosch_2018.dbc starts ";
CM_ "Imported file _bosch_2018.dbc starts h
CM_ "Imported file _bosch_2018.dbc starts";
CM_ "Imported file _bosch_2018.dbc starts 
CM_ "Imported file _bosch_2018.dbc starts ";
CM_ "Imported file _bosch_2018.dbc starts h
CM_ "Imported file _bosch_2018.dbc starts ";
CM_ "Imported file _bosch_2018.dbc starts h
CM_ "Imported file _bosch_2018.dbc starts h";
CM_ "Imported file _bosch_2018.dbc starts he
CM_ "Imported file _bosch_2018.dbc start";
CM_ "Imported file _bosch_2018.dbc starts
CM_ "Imported file _bosch_2018.dbc start";
CM_ "Imported file _bosch_2018.dbc starts
CM_ "Imported file _bosch_2018.dbc starts";
CM_ "Imported file _bosch_2018.dbc starts 
CM_ "Imported file _bosch_2018.dbc starts ";
CM_ "Imported file _bosch_2018.dbc starts h
CM_ "Imported file _bosch_2018.dbc starts";
CM_ "Imported file _bosch_2018.dbc starts 
CM_ "Imported file _bosch_2018.dbc starts ";
CM_ "Imported file _bosch_2018.dbc starts h
CM_ "Imported file _bosch_2018.dbc starts ";
CM_ "Imported file _bosch_2018.dbc starts h
CM_ "Imported file _bosch_2018.dbc starts h";
CM_ "Imported file _bosch_2018.dbc starts he
CM_ "Imported file _bosch_2018.dbc starts";
CM_ "Imported file _bosch_2018.dbc starts 
CM_ "Imported file _bosch_2018.dbc starts ";
CM_ "Imported file _bosch_2018.dbc starts h
CM_ "Imported file _bosch_2018.dbc starts ";
CM_ "Imported file _bosch_2018.dbc starts h
CM_ "Imported file _bosch_2018.dbc starts h";
CM_ "Imported file _bosch_2018.dbc starts he
CM_ "Imported file _bosch_2018.dbc starts ";
CM_ "Imported file _bosch_2018.dbc starts h
CM_ "Imported file _bosch_2018.dbc starts h";
CM_ "Imported file _bosch_2018.dbc starts he
CM_ "Imported file _bosch_2018.dbc starts h";
CM_ "Imported file _bosch_2018.dbc starts he
CM_ "Imported file _bosch_2018.dbc starts he";
CM_ "Imported file _bosch_2018.dbc starts her
CM_ "Imported file _bosch_2018.dbc star";
CM_ "Imported file _bosch_2018.dbc start
CM_ "Imported file _bosch_2018.dbc start";
CM_ "Imported file _bosch_2018.dbc starts
CM_ "Imported file _bosch_2018.dbc star";
CM_ "Imported file _bosch_2018.dbc start
CM_ "Imported file _bosch_2018.dbc start";
CM_ "Imported file _bosch_2018.dbc starts
CM_ "Imported file _bosch_2018.dbc start";
CM_ "Imported file _bosch_2018.dbc starts
CM_ "Imported file _bosch_2018.dbc start";
CM_ "Imported file _bosch_2018.dbc starts
CM_ "Imported file _bosch_2018.dbc starts";
CM_ "Imported file _bosch_2018.dbc starts 
CM_ "Imported file _bosch_2018.dbc starts ";
CM_ "Imported file _bosch_2018.dbc starts h
CM_ "Imported file _bosch_2018.dbc start";
CM_ "Imported file _bosch_2018.dbc starts
CM_ "Imported file _bosch_2018.dbc start";
CM_ "Imported file _bosch_2018.dbc starts
CM_ "Imported file _bosch_2018.dbc starts";
CM_ "Imported file _bosch_2018.dbc starts 
CM_ "Imported file _bosch_2018.dbc starts ";
CM_ "Imported file _bosch_2018.dbc starts h
CM_ "Imported file _bosch_2018.dbc starts";
CM_ "Imported file _bosch_2018.dbc starts 
CM_ "Imported file _bosch_2018.dbc starts ";
CM_ "Imported file _bosch_2018.dbc starts h
CM_ "Imported file _bosch_2018.dbc starts ";
CM_ "Imported file _bosch_2018.dbc starts h
CM_ "Imported file _bosch_2018.dbc starts h";
CM_ "Imported file _bosch_2018.dbc starts he
CM_ "Imported file _bosch_2018.dbc start";
CM_ "Imported file _bosch_2018.dbc starts
CM_ "Imported file _bosch_2018.dbc start";
CM_ "Imported file _bosch_2018.dbc starts
CM_ "Imported file _bosch_2018.dbc starts";
CM_ "Imported file _bosch_2018.dbc starts 
CM_ "Imported file _bosch_2018.dbc starts ";
CM_ "Imported file _bosch_2018.dbc starts h
CM_ "Imported file _bosch_2018.dbc starts";
CM_ "Imported file _bosch_2018.dbc starts 
CM_ "Imported file _bosch_2018.dbc starts ";
CM_ "Imported file _bosch_2018.dbc starts h
CM_ "Imported file _bosch_2018.dbc starts ";
CM_ "Imported file _bosch_2018.dbc starts h
CM_ "Imported file _bosch_2018.dbc starts h";
CM_ "Imported file _bosch_2018.dbc starts he
CM_ "Imported file _bosch_2018.dbc starts";
CM_ "Imported file _bosch_2018.dbc starts 
CM_ "Imported file _bosch_2018.dbc starts ";
CM_ "Imported file _bosch_2018.dbc starts h
CM_ "Imported file _bosch_2018.dbc starts ";
CM_ "Imported file _bosch_2018.dbc starts h
CM_ "Imported file _bosch_2018.dbc starts h";
CM_ "Imported file _bosch_2018.dbc starts he
CM_ "Imported file _bosch_2018.dbc starts ";
CM_ "Imported file _bosch_2018.dbc starts h
CM_ "Imported file _bosch_2018.dbc starts h";
CM_ "Imported file _bosch_2018.dbc starts he
CM_ "Imported file _bosch_2018.dbc starts h";
CM_ "Imported file _bosch_2018.dbc starts he
CM_ "Imported file _bosch_2018.dbc starts he";
CM_ "Imported file _bosch_2018.dbc starts her
CM_ "Imported file _bosch_2018.dbc start";
CM_ "Imported file _bosch_2018.dbc starts
CM_ "Imported file _bosch_2018.dbc start";
CM_ "Imported file _bosch_2018.dbc starts
CM_ "Imported file _bosch_2018.dbc starts";
CM_ "Imported file _bosch_2018.dbc starts 
CM_ "Imported file _bosch_2018.dbc starts ";
CM_ "Imported file _bosch_2018.dbc starts h
CM_ "Imported file _bosch_2018.dbc starts";
CM_ "Imported file _bosch_2018.dbc starts 
CM_ "Imported file _bosch_2018.dbc starts ";
CM_ "Imported file _bosch_2018.dbc starts h
CM_ "Imported file _bosch_2018.dbc starts ";
CM_ "Imported file _bosch_2018.dbc starts h
CM_ "Imported file _bosch_2018.dbc starts h";
CM_ "Imported file _bosch_2018.dbc starts he
CM_ "Imported file _bosch_2018.dbc starts";
CM_ "Imported file _bosch_2018.dbc starts 
CM_ "Imported file _bosch_2018.dbc starts ";
CM_ "Imported file _bosch_2018.dbc starts h
CM_ "Imported file _bosch_2018.dbc starts ";
CM_ "Imported file _bosch_2018.dbc starts h
CM_ "Imported file _bosch_2018.dbc starts h";
CM_ "Imported file _bosch_2018.dbc starts he
CM_ "Imported file _bosch_2018.dbc starts ";
CM_ "Imported file _bosch_2018.dbc starts h
CM_ "Imported file _bosch_2018.dbc starts h";
CM_ "Imported file _bosch_2018.dbc starts he
CM_ "Imported file _bosch_2018.dbc starts h";
CM_ "Imported file _bosch_2018.dbc starts he
CM_ "Imported file _bosch_2018.dbc starts he";
CM_ "Imported file _bosch_2018.dbc starts her
CM_ "Imported file _bosch_2018.dbc starts";
CM_ "Imported file _bosch_2018.dbc starts 
CM_ "Imported file _bosch_2018.dbc starts ";
CM_ "Imported file _bosch_2018.dbc starts h
CM_ "Imported file _bosch_2018.dbc starts ";
CM_ "Imported file _bosch_2018.dbc starts h
CM_ "Imported file _bosch_2018.dbc starts h";
CM_ "Imported file _bosch_2018.dbc starts he
CM_ "Imported file _bosch_2018.dbc starts ";
CM_ "Imported file _bosch_2018.dbc starts h
CM_ "Imported file _bosch_2018.dbc starts h";
CM_ "Imported file _bosch_2018.dbc starts he
CM_ "Imported file _bosch_2018.dbc starts h";
CM_ "Imported file _bosch_2018.dbc starts he
CM_ "Imported file _bosch_2018.dbc starts he";
CM_ "Imported file _bosch_2018.dbc starts her
CM_ "Imported file _bosch_2018.dbc starts ";
CM_ "Imported file _bosch_2018.dbc starts h
CM_ "Imported file _bosch_2018.dbc starts h";
CM_ "Imported file _bosch_2018.dbc starts he
CM_ "Imported file _bosch_2018.dbc starts h";
CM_ "Imported file _bosch_2018.dbc starts he
CM_ "Imported file _bosch_2018.dbc starts he";
CM_ "Imported file _bosch_2018.dbc starts her
CM_ "Imported file _bosch_2018.dbc starts h";
CM_ "Imported file _bosch_2018.dbc starts he
CM_ "Imported file _bosch_2018.dbc starts he";
CM_ "Imported file _bosch_2018.dbc starts her
CM_ "Imported file _bosch_2018.dbc starts he";
CM_ "Imported file _bosch_2018.dbc starts her
CM_ "Imported file _bosch_2018.dbc starts her";
CM_ "Imported file _bosch_2018.dbc starts here
CM_ "Imported file _bosch_2018.dbc sta";
CM_ "Imported file _bosch_2018.dbc star
CM_ "Imported file _bosch_2018.dbc star";
CM_ "Imported file _bosch_2018.dbc start
CM_ "Imported file _bosch_2018.dbc star";
CM_ "Imported file _bosch_2018.dbc start
CM_ "Imported file _bosch_2018.dbc start";
CM_ "Imported file _bosch_2018.dbc starts
CM_ "Imported file _bosch_2018.dbc sta";
CM_ "Imported file _bosch_2018.dbc star
CM_ "Imported file _bosch_2018.dbc star";
CM_ "Imported file _bosch_2018.dbc start
CM_ "Imported file _bosch_2018.dbc star";
CM_ "Imported file _bosch_2018.dbc start
CM_ "Imported file _bosch_2018.dbc start";
CM_ "Imported file _bosch_2018.dbc starts
CM_ "Imported file _bosch_2018.dbc star";
CM_ "Imported file _bosch_2018.dbc start
CM_ "Imported file _bosch_2018.dbc start";
CM_ "Imported file _bosch_2018.dbc starts
CM_ "Imported file _bosch_2018.dbc star";
CM_ "Imported file _bosch_2018.dbc start
CM_ "Imported file _bosch_2018.dbc start";
CM_ "Imported file _bosch_2018.dbc starts
CM_ "Imported file _bosch_2018.dbc start";
CM_ "Imported file _bosch_2018.dbc starts
CM_ "Imported file _bosch_2018.dbc start";
CM_ "Imported file _bosch_2018.dbc starts
CM_ "Imported file _bosch_2018.dbc starts";
CM_ "Imported file _bosch_2018.dbc starts 
CM_ "Imported file _bosch_2018.dbc starts ";
CM_ "Imported file _bosch_2018.dbc starts h
CM_ "Imported file _bosch_2018.dbc star";
CM_ "Imported file _bosch_2018.dbc start
CM_ "Imported file _bosch_2018.dbc start";
CM_ "Imported file _bosch_2018.dbc starts
CM_ "Imported file _bosch_2018.dbc star";
CM_ "Imported file _bosch_2018.dbc start
CM_ "Imported file _bosch_2018.dbc start";
CM_ "Imported file _bosch_2018.dbc starts
CM_ "Imported file _bosch_2018.dbc start";
CM_ "Imported file _bosch_2018.dbc starts
CM_ "Imported file _bosch_2018.dbc start";
CM_ "Imported file _bosch_2018.dbc starts
CM_ "Imported file _bosch_2018.dbc starts";
CM_ "Imported file _bosch_2018.dbc starts 
CM_ "Imported file _bosch_2018.dbc starts ";
CM_ "Imported file _bosch_2018.dbc starts h
CM_ "Imported file _bosch_2018.dbc start";
CM_ "Imported file _bosch_2018.dbc starts
CM_ "Imported file _bosch_2018.dbc start";
CM_ "Imported file _bosch_2018.dbc starts
CM_ "Imported file _bosch_2018.dbc starts";
CM_ "Imported file _bosch_2018.dbc starts 
CM_ "Imported file _bosch_2018.dbc starts ";
CM_ "Imported file _bosch_2018.dbc starts h
CM_ "Imported file _bosch_2018.dbc starts";
CM_ "Imported file _bosch_2018.dbc starts 
CM_ "Imported file _bosch_2018.dbc starts ";
CM_ "Imported file _bosch_2018.dbc starts h
CM_ "Imported file _bosch_2018.dbc starts ";
CM_ "Imported file _bosch_2018.dbc starts h
CM_ "Imported file _bosch_2018.dbc starts h";
CM_ "Imported file _bosch_2018.dbc starts he
CM_ "Imported file _bosch_2018.dbc star";
CM_ "Imported file _bosch_2018.dbc start
CM_ "Imported file _bosch_2018.dbc start";
CM_ "Imported file _bosch_2018.dbc starts
CM_ "Imported file _bosch_2018.dbc star";
CM_ "Imported file _bosch_2018.dbc start
CM_ "Imported file _bosch_2018.dbc start";
CM_ "Imported file _bosch_2018.dbc starts
CM_ "Imported file _bosch_2018.dbc start";
CM_ "Imported file _bosch_2018.dbc starts
CM_ "Imported file _bosch_2018.dbc start";
CM_ "Imported file _bosch_2018.dbc starts
CM_ "Imported file _bosch_2018.dbc starts";
CM_ "Imported file _bosch_2018.dbc starts 
CM_ "Imported file _bosch_2018.dbc starts ";
CM_ "Imported file _bosch_2018.dbc starts h
CM_ "Imported file _bosch_2018.dbc start";
CM_ "Imported file _bosch_2018.dbc starts
CM_ "Imported file _bosch_2018.dbc start";
CM_ "Imported file _bosch_2018.dbc starts
CM_ "Imported file _bosch_2018.dbc starts";
CM_ "Imported file _bosch_2018.dbc starts 
CM_ "Imported file _bosch_2018.dbc starts ";
CM_ "Imported file _bosch_2018.dbc starts h
CM_ "Imported file _bosch_2018.dbc starts";
CM_ "Imported file _bosch_2018.dbc starts 
CM_ "Imported file _bosch_2018.dbc starts ";
CM_ "Imported file _bosch_2018.dbc starts h
CM_ "Imported file _bosch_2018.dbc starts ";
CM_ "Imported file _bosch_2018.dbc starts h
CM_ "Imported file _bosch_2018.dbc starts h";
CM_ "Imported file _bosch_2018.dbc starts he
CM_ "Imported file _bosch_2018.dbc start";
CM_ "Imported file _bosch_2018.dbc starts
CM_ "Imported file _bosch_2018.dbc start";
CM_ "Imported file _bosch_2018.dbc starts
CM_ "Imported file _bosch_2018.dbc starts";
CM_ "Imported file _bosch_2018.dbc starts 
CM_ "Imported file _bosch_2018.dbc starts ";
CM_ "Imported file _bosch_2018.dbc starts h
CM_ "Imported file _bosch_2018.dbc starts";
CM_ "Imported file _bosch_2018.dbc starts 
CM_ "Imported file _bosch_2018.dbc starts ";
CM_ "Imported file _bosch_2018.dbc starts h
CM_ "Imported file _bosch_2018.dbc starts ";
CM_ "Imported file _bosch_2018.dbc starts h
CM_ "Imported file _bosch_2018.dbc starts h";
CM_ "Imported file _bosch_2018.dbc starts he
CM_ "Imported file _bosch_2018.dbc starts";
CM_ "Imported file _bosch_2018.dbc starts 
CM_ "Imported file _bosch_2018.dbc starts ";
CM_ "Imported file _bosch_2018.dbc starts h
CM_ "Imported file _bosch_2018.dbc starts ";
CM_ "Imported file _bosch_2018.dbc starts h
CM_ "Imported file _bosch_2018.dbc starts h";
CM_ "Imported file _bosch_2018.dbc starts he
CM_ "Imported file _bosch_2018.dbc starts ";
CM_ "Imported file _bosch_2018.dbc starts h
CM_ "Imported file _bosch_2018.dbc starts h";
CM_ "Imported file _bosch_2018.dbc starts he
CM_ "Imported file _bosch_2018.dbc starts h";
CM_ "Imported file _bosch_2018.dbc starts he
CM_ "Imported file _bosch_2018.dbc starts he";
CM_ "Imported file _bosch_2018.dbc starts her
CM_ "Imported file _bosch_2018.dbc star";
CM_ "Imported file _bosch_2018.dbc start
CM_ "Imported file _bosch_2018.dbc start";
CM_ "Imported file _bosch_2018.dbc starts
CM_ "Imported file _bosch_2018.dbc star";
CM_ "Imported file _bosch_2018.dbc start
CM_ "Imported file _bosch_2018.dbc start";
CM_ "Imported file _bosch_2018.dbc starts
CM_ "Imported file _bosch_2018.dbc start";
CM_ "Imported file _bosch_2018.dbc starts
CM_ "Imported file _bosch_2018.dbc start";
CM_ "Imported file _bosch_2018.dbc starts
CM_ "Imported file _bosch_2018.dbc starts";
CM_ "Imported file _bosch_2018.dbc starts 
CM_ "Imported file _bosch_2018.dbc starts ";
CM_ "Imported file _bosch_2018.dbc starts h
CM_ "Imported file _bosch_2018.dbc start";
CM_ "Imported file _bosch_2018.dbc starts
CM_ "Imported file _bosch_2018.dbc start";
CM_ "Imported file _bosch_2018.dbc starts
CM_ "Imported file _bosch_2018.dbc starts";
CM_ "Imported file _bosch_2018.dbc starts 
CM_ "Imported file _bosch_2018.dbc starts ";
CM_ "Imported file _bosch_2018.dbc starts h
CM_ "Imported file _bosch_2018.dbc starts";
CM_ "Imported file _bosch_2018.dbc starts 
CM_ "Imported file _bosch_2018.dbc starts ";
CM_ "Imported file _bosch_2018.dbc starts h
CM_ "Imported file _bosch_2018.dbc starts ";
CM_ "Imported file _bosch_2018.dbc starts h
CM_ "Imported file _bosch_2018.dbc starts h";
CM_ "Imported file _bosch_2018.dbc starts he
CM_ "Imported file _bosch_2018.dbc start";
CM_ "Imported file _bosch_2018.dbc starts
CM_ "Imported file _bosch_2018.dbc start";
CM_ "Imported file _bosch_2018.dbc starts
CM_ "Imported file _bosch_2018.dbc starts";
CM_ "Imported file _bosch_2018.dbc starts 
CM_ "Imported file _bosch_2018.dbc starts ";
CM_ "Imported file _bosch_2018.dbc starts h
CM_ "Imported file _bosch_2018.dbc starts";
CM_ "Imported file _bosch_2018.dbc starts 
CM_ "Imported file _bosch_2018.dbc starts ";
CM_ "Imported file _bosch_2018.dbc starts h
CM_ "Imported file _bosch_2018.dbc starts ";
CM_ "Imported file _bosch_2018.dbc starts h
CM_ "Imported file _bosch_2018.dbc starts h";
CM_ "Imported file _bosch_2018.dbc starts he
CM_ "Imported file _bosch_2018.dbc starts";
CM_ "Imported file _bosch_2018.dbc starts 
CM_ "Imported file _bosch_2018.dbc starts ";
CM_ "Imported file _bosch_2018.dbc starts h
CM_ "Imported file _bosch_2018.dbc starts ";
CM_ "Imported file _bosch_2018.dbc starts h
CM_ "Imported file _bosch_2018.dbc starts h";
CM_ "Imported file _bosch_2018.dbc starts he
CM_ "Imported file _bosch_2018.dbc starts ";
CM_ "Imported file _bosch_2018.dbc starts h
CM_ "Imported file _bosch_2018.dbc starts h";
CM_ "Imported file _bosch_2018.dbc starts he
CM_ "Imported file _bosch_2018.dbc starts h";
CM_ "Imported file _bosch_2018.dbc starts he
CM_ "Imported file _bosch_2018.dbc starts he";
CM_ "Imported file _bosch_2018.dbc starts her
CM_ "Imported file _bosch_2018.dbc start";
CM_ "Imported file _bosch_2018.dbc starts
CM_ "Imported file _bosch_2018.dbc start";
CM_ "Imported file _bosch_2018.dbc starts
CM_ "Imported file _bosch_2018.dbc starts";
CM_ "Imported file _bosch_2018.dbc starts 
CM_ "Imported file _bosch_2018.dbc starts ";
CM_ "Imported file _bosch_2018.dbc starts h
CM_ "Imported file _bosch_2018.dbc starts";
CM_ "Imported file _bosch_2018.dbc starts 
CM_ "Imported file _bosch_2018.dbc starts ";
CM_ "Imported file _bosch_2018.dbc starts h
CM_ "Imported file _bosch_2018.dbc starts ";
CM_ "Imported file _bosch_2018.dbc starts h
CM_ "Imported file _bosch_2018.dbc starts h";
CM_ "Imported file _bosch_2018.dbc starts he
CM_ "Imported file _bosch_2018.dbc starts";
CM_ "Imported file _bosch_2018.dbc starts 
CM_ "Imported file _bosch_2018.dbc starts ";
CM_ "Imported file _bosch_2018.dbc starts h
CM_ "Imported file _bosch_2018.dbc starts ";
CM_ "Imported file _bosch_2018.dbc starts h
CM_ "Imported file _bosch_2018.dbc starts h";
CM_ "Imported file _bosch_2018.dbc starts he
CM_ "Imported file _bosch_2018.dbc starts ";
CM_ "Imported file _bosch_2018.dbc starts h
CM_ "Imported file _bosch_2018.dbc starts h";
CM_ "Imported file _bosch_2018.dbc starts he
CM_ "Imported file _bosch_2018.dbc starts h";
CM_ "Imported file _bosch_2018.dbc starts he
CM_ "Imported file _bosch_2018.dbc starts he";
CM_ "Imported file _bosch_2018.dbc starts her
CM_ "Imported file _bosch_2018.dbc starts";
CM_ "Imported file _bosch_2018.dbc starts 
CM_ "Imported file _bosch_2018.dbc starts ";
CM_ "Imported file _bosch_2018.dbc starts h
CM_ "Imported file _bosch_2018.dbc starts ";
CM_ "Imported file _bosch_2018.dbc starts h
CM_ "Imported file _bosch_2018.dbc starts h";
CM_ "Imported file _bosch_2018.dbc starts he
CM_ "Imported file _bosch_2018.dbc starts ";
CM_ "Imported file _bosch_2018.dbc starts h
CM_ "Imported file _bosch_2018.dbc starts h";
CM_ "Imported file _bosch_2018.dbc starts he
CM_ "Imported file _bosch_2018.dbc starts h";
CM_ "Imported file _bosch_2018.dbc starts he
CM_ "Imported file _bosch_2018.dbc starts he";
CM_ "Imported file _bosch_2018.dbc starts her
CM_ "Imported file _bosch_2018.dbc starts ";
CM_ "Imported file _bosch_2018.dbc starts h
CM_ "Imported file _bosch_2018.dbc starts h";
CM_ "Imported file _bosch_2018.dbc starts he
CM_ "Imported file _bosch_2018.dbc starts h";
CM_ "Imported file _bosch_2018.dbc starts he
CM_ "Imported file _bosch_2018.dbc starts he";
CM_ "Imported file _bosch_2018.dbc starts her
CM_ "Imported file _bosch_2018.dbc starts h";
CM_ "Imported file _bosch_2018.dbc starts he
CM_ "Imported file _bosch_2018.dbc starts he";
CM_ "Imported file _bosch_2018.dbc starts her
CM_ "Imported file _bosch_2018.dbc starts he";
CM_ "Imported file _bosch_2018.dbc starts her
CM_ "Imported file _bosch_2018.dbc starts her";
CM_ "Imported file _bosch_2018.dbc starts here
CM_ "Imported file _bosch_2018.dbc star";
CM_ "Imported file _bosch_2018.dbc start
CM_ "Imported file _bosch_2018.dbc start";
CM_ "Imported file _bosch_2018.dbc starts
CM_ "Imported file _bosch_2018.dbc star";
CM_ "Imported file _bosch_2018.dbc start
CM_ "Imported file _bosch_2018.dbc start";
CM_ "Imported file _bosch_2018.dbc starts
CM_ "Imported file _bosch_2018.dbc start";
CM_ "Imported file _bosch_2018.dbc starts
CM_ "Imported file _bosch_2018.dbc start";
CM_ "Imported file _bosch_2018.dbc starts
CM_ "Imported file _bosch_2018.dbc starts";
CM_ "Imported file _bosch_2018.dbc starts 
CM_ "Imported file _bosch_2018.dbc starts ";
CM_ "Imported file _bosch_2018.dbc starts h
CM_ "Imported file _bosch_2018.dbc start";
CM_ "Imported file _bosch_2018.dbc starts
CM_ "Imported file _bosch_2018.dbc start";
CM_ "Imported file _bosch_2018.dbc starts
CM_ "Imported file _bosch_2018.dbc starts";
CM_ "Imported file _bosch_2018.dbc starts 
CM_ "Imported file _bosch_2018.dbc starts ";
CM_ "Imported file _bosch_2018.dbc starts h
CM_ "Imported file _bosch_2018.dbc starts";
CM_ "Imported file _bosch_2018.dbc starts 
CM_ "Imported file _bosch_2018.dbc starts ";
CM_ "Imported file _bosch_2018.dbc starts h
CM_ "Imported file _bosch_2018.dbc starts ";
CM_ "Imported file _bosch_2018.dbc starts h
CM_ "Imported file _bosch_2018.dbc starts h";
CM_ "Imported file _bosch_2018.dbc starts he
CM_ "Imported file _bosch_2018.dbc start";
CM_ "Imported file _bosch_2018.dbc starts
CM_ "Imported file _bosch_2018.dbc start";
CM_ "Imported file _bosch_2018.dbc starts
CM_ "Imported file _bosch_2018.dbc starts";
CM_ "Imported file _bosch_2018.dbc starts 
CM_ "Imported file _bosch_2018.dbc starts ";
CM_ "Imported file _bosch_2018.dbc starts h
CM_ "Imported file _bosch_2018.dbc starts";
CM_ "Imported file _bosch_2018.dbc starts 
CM_ "Imported file _bosch_2018.dbc starts ";
CM_ "Imported file _bosch_2018.dbc starts h
CM_ "Imported file _bosch_2018.dbc starts ";
CM_ "Imported file _bosch_2018.dbc starts h
CM_ "Imported file _bosch_2018.dbc starts h";
CM_ "Imported file _bosch_2018.dbc starts he
CM_ "Imported file _bosch_2018.dbc starts";
CM_ "Imported file _bosch_2018.dbc starts 
CM_ "Imported file _bosch_2018.dbc starts ";
CM_ "Imported file _bosch_2018.dbc starts h
CM_ "Imported file _bosch_2018.dbc starts ";
CM_ "Imported file _bosch_2018.dbc starts h
CM_ "Imported file _bosch_2018.dbc starts h";
CM_ "Imported file _bosch_2018.dbc starts he
CM_ "Imported file _bosch_2018.dbc starts ";
CM_ "Imported file _bosch_2018.dbc starts h
CM_ "Imported file _bosch_2018.dbc starts h";
CM_ "Imported file _bosch_2018.dbc starts he
CM_ "Imported file _bosch_2018.dbc starts h";
CM_ "Imported file _bosch_2018.dbc starts he
CM_ "Imported file _bosch_2018.dbc starts he";
CM_ "Imported file _bosch_2018.dbc starts her
CM_ "Imported file _bosch_2018.dbc start";
CM_ "Imported file _bosch_2018.dbc starts
CM_ "Imported file _bosch_2018.dbc start";
CM_ "Imported file _bosch_2018.dbc starts
CM_ "Imported file _bosch_2018.dbc starts";
CM_ "Imported file _bosch_2018.dbc starts 
CM_ "Imported file _bosch_2018.dbc starts ";
CM_ "Imported file _bosch_2018.dbc starts h
CM_ "Imported file _bosch_2018.dbc starts";
CM_ "Imported file _bosch_2018.dbc starts 
CM_ "Imported file _bosch_2018.dbc starts ";
CM_ "Imported file _bosch_2018.dbc starts h
CM_ "Imported file _bosch_2018.dbc starts ";
CM_ "Imported file _bosch_2018.dbc starts h
CM_ "Imported file _bosch_2018.dbc starts h";
CM_ "Imported file _bosch_2018.dbc starts he
CM_ "Imported file _bosch_2018.dbc starts";
CM_ "Imported file _bosch_2018.dbc starts 
CM_ "Imported file _bosch_2018.dbc starts ";
CM_ "Imported file _bosch_2018.dbc starts h
CM_ "Imported file _bosch_2018.dbc starts ";
CM_ "Imported file _bosch_2018.dbc starts h
CM_ "Imported file _bosch_2018.dbc starts h";
CM_ "Imported file _bosch_2018.dbc starts he
CM_ "Imported file _bosch_2018.dbc starts ";
CM_ "Imported file _bosch_2018.dbc starts h
CM_ "Imported file _bosch_2018.dbc starts h";
CM_ "Imported file _bosch_2018.dbc starts he
CM_ "Imported file _bosch_2018.dbc starts h";
CM_ "Imported file _bosch_2018.dbc starts he
CM_ "Imported file _bosch_2018.dbc starts he";
CM_ "Imported file _bosch_2018.dbc starts her
CM_ "Imported file _bosch_2018.dbc starts";
CM_ "Imported file _bosch_2018.dbc starts 
CM_ "Imported file _bosch_2018.dbc starts ";
CM_ "Imported file _bosch_2018.dbc starts h
CM_ "Imported file _bosch_2018.dbc starts ";
CM_ "Imported file _bosch_2018.dbc starts h
CM_ "Imported file _bosch_2018.dbc starts h";
CM_ "Imported file _bosch_2018.dbc starts he
CM_ "Imported file _bosch_2018.dbc starts ";
CM_ "Imported file _bosch_2018.dbc starts h
CM_ "Imported file _bosch_2018.dbc starts h";
CM_ "Imported file _bosch_2018.dbc starts he
CM_ "Imported file _bosch_2018.dbc starts h";
CM_ "Imported file _bosch_2018.dbc starts he
CM_ "Imported file _bosch_2018.dbc starts he";
CM_ "Imported file _bosch_2018.dbc starts her
CM_ "Imported file _bosch_2018.dbc starts ";
CM_ "Imported file _bosch_2018.dbc starts h
CM_ "Imported file _bosch_2018.dbc starts h";
CM_ "Imported file _bosch_2018.dbc starts he
CM_ "Imported file _bosch_2018.dbc starts h";
CM_ "Imported file _bosch_2018.dbc starts he
CM_ "Imported file _bosch_2018.dbc starts he";
CM_ "Imported file _bosch_2018.dbc starts her
CM_ "Imported file _bosch_2018.dbc starts h";
CM_ "Imported file _bosch_2018.dbc starts he
CM_ "Imported file _bosch_2018.dbc starts he";
CM_ "Imported file _bosch_2018.dbc starts her
CM_ "Imported file _bosch_2018.dbc starts he";
CM_ "Imported file _bosch_2018.dbc starts her
CM_ "Imported file _bosch_2018.dbc starts her";
CM_ "Imported file _bosch_2018.dbc starts here
CM_ "Imported file _bosch_2018.dbc start";
CM_ "Imported file _bosch_2018.dbc starts
CM_ "Imported file _bosch_2018.dbc start";
CM_ "Imported file _bosch_2018.dbc starts
CM_ "Imported file _bosch_2018.dbc starts";
CM_ "Imported file _bosch_2018.dbc starts 
CM_ "Imported file _bosch_2018.dbc starts ";
CM_ "Imported file _bosch_2018.dbc starts h
CM_ "Imported file _bosch_2018.dbc starts";
CM_ "Imported file _bosch_2018.dbc starts 
CM_ "Imported file _bosch_2018.dbc starts ";
CM_ "Imported file _bosch_2018.dbc starts h
CM_ "Imported file _bosch_2018.dbc starts ";
CM_ "Imported file _bosch_2018.dbc starts h
CM_ "Imported file _bosch_2018.dbc starts h";
CM_ "Imported file _bosch_2018.dbc starts he
CM_ "Imported file _bosch_2018.dbc starts";
CM_ "Imported file _bosch_2018.dbc starts 
CM_ "Imported file _bosch_2018.dbc starts ";
CM_ "Imported file _bosch_2018.dbc starts h
CM_ "Imported file _bosch_2018.dbc starts ";
CM_ "Imported file _bosch_2018.dbc starts h
CM_ "Imported file _bosch_2018.dbc starts h";
CM_ "Imported file _bosch_2018.dbc starts he
CM_ "Imported file _bosch_2018.dbc starts ";
CM_ "Imported file _bosch_2018.dbc starts h
CM_ "Imported file _bosch_2018.dbc starts h";
CM_ "Imported file _bosch_2018.dbc starts he
CM_ "Imported file _bosch_2018.dbc starts h";
CM_ "Imported file _bosch_2018.dbc starts he
CM_ "Imported file _bosch_2018.dbc starts he";
CM_ "Imported file _bosch_2018.dbc starts her
CM_ "Imported file _bosch_2018.dbc starts";
CM_ "Imported file _bosch_2018.dbc starts 
CM_ "Imported file _bosch_2018.dbc starts ";
CM_ "Imported file _bosch_2018.dbc starts h
CM_ "Imported file _bosch_2018.dbc starts ";
CM_ "Imported file _bosch_2018.dbc starts h
CM_ "Imported file _bosch_2018.dbc starts h";
CM_ "Imported file _bosch_2018.dbc starts he
CM_ "Imported file _bosch_2018.dbc starts ";
CM_ "Imported file _bosch_2018.dbc starts h
CM_ "Imported file _bosch_2018.dbc starts h";
CM_ "Imported file _bosch_2018.dbc starts he
CM_ "Imported file _bosch_2018.dbc starts h";
CM_ "Imported file _bosch_2018.dbc starts he
CM_ "Imported file _bosch_2018.dbc starts he";
CM_ "Imported file _bosch_2018.dbc starts her
CM_ "Imported file _bosch_2018.dbc starts ";
CM_ "Imported file _bosch_2018.dbc starts h
CM_ "Imported file _bosch_2018.dbc starts h";
CM_ "Imported file _bosch_2018.dbc starts he
CM_ "Imported file _bosch_2018.dbc starts h";
CM_ "Imported file _bosch_2018.dbc starts he
CM_ "Imported file _bosch_2018.dbc starts he";
CM_ "Imported file _bosch_2018.dbc starts her
CM_ "Imported file _bosch_2018.dbc starts h";
CM_ "Imported file _bosch_2018.dbc starts he
CM_ "Imported file _bosch_2018.dbc starts he";
CM_ "Imported file _bosch_2018.dbc starts her
CM_ "Imported file _bosch_2018.dbc starts he";
CM_ "Imported file _bosch_2018.dbc starts her
CM_ "Imported file _bosch_2018.dbc starts her";
CM_ "Imported file _bosch_2018.dbc starts here
CM_ "Imported file _bosch_2018.dbc starts";
CM_ "Imported file _bosch_2018.dbc starts 
CM_ "Imported file _bosch_2018.dbc starts ";
CM_ "Imported file _bosch_2018.dbc starts h
CM_ "Imported file _bosch_2018.dbc starts ";
CM_ "Imported file _bosch_2018.dbc starts h
CM_ "Imported file _bosch_2018.dbc starts h";
CM_ "Imported file _bosch_2018.dbc starts he
CM_ "Imported file _bosch_2018.dbc starts ";
CM_ "Imported file _bosch_2018.dbc starts h
CM_ "Imported file _bosch_2018.dbc starts h";
CM_ "Imported file _bosch_2018.dbc starts he
CM_ "Imported file _bosch_2018.dbc starts h";
CM_ "Imported file _bosch_2018.dbc starts he
CM_ "Imported file _bosch_2018.dbc starts he";
CM_ "Imported file _bosch_2018.dbc starts her
CM_ "Imported file _bosch_2018.dbc starts ";
CM_ "Imported file _bosch_2018.dbc starts h
CM_ "Imported file _bosch_2018.dbc starts h";
CM_ "Imported file _bosch_2018.dbc starts he
CM_ "Imported file _bosch_2018.dbc starts h";
CM_ "Imported file _bosch_2018.dbc starts he
CM_ "Imported file _bosch_2018.dbc starts he";
CM_ "Imported file _bosch_2018.dbc starts her
CM_ "Imported file _bosch_2018.dbc starts h";
CM_ "Imported file _bosch_2018.dbc starts he
CM_ "Imported file _bosch_2018.dbc starts he";
CM_ "Imported file _bosch_2018.dbc starts her
CM_ "Imported file _bosch_2018.dbc starts he";
CM_ "Imported file _bosch_2018.dbc starts her
CM_ "Imported file _bosch_2018.dbc starts her";
CM_ "Imported file _bosch_2018.dbc starts here
CM_ "Imported file _bosch_2018.dbc starts ";
CM_ "Imported file _bosch_2018.dbc starts h
CM_ "Imported file _bosch_2018.dbc starts h";
CM_ "Imported file _bosch_2018.dbc starts he
CM_ "Imported file _bosch_2018.dbc starts h";
CM_ "Imported file _bosch_2018.dbc starts he
CM_ "Imported file _bosch_2018.dbc starts he";
CM_ "Imported file _bosch_2018.dbc starts her
CM_ "Imported file _bosch_2018.dbc starts h";
CM_ "Imported file _bosch_2018.dbc starts he
CM_ "Imported file _bosch_2018.dbc starts he";
CM_ "Imported file _bosch_2018.dbc starts her
CM_ "Imported file _bosch_2018.dbc starts he";
CM_ "Imported file _bosch_2018.dbc starts her
CM_ "Imported file _bosch_2018.dbc starts her";
CM_ "Imported file _bosch_2018.dbc starts here
CM_ "Imported file _bosch_2018.dbc starts h";
CM_ "Imported file _bosch_2018.dbc starts he
CM_ "Imported file _bosch_2018.dbc starts he";
CM_ "Imported file _bosch_2018.dbc starts her
CM_ "Imported file _bosch_2018.dbc starts he";
CM_ "Imported file _bosch_2018.dbc starts her
CM_ "Imported file _bosch_2018.dbc starts her";
CM_ "Imported file _bosch_2018.dbc starts here
CM_ "Imported file _bosch_2018.dbc starts he";
CM_ "Imported file _bosch_2018.dbc starts her
CM_ "Imported file _bosch_2018.dbc starts her";
CM_ "Imported file _bosch_2018.dbc starts here
CM_ "Imported file _bosch_2018.dbc starts her";
CM_ "Imported file _bosch_2018.dbc starts here
CM_ "Imported file _bosch_2018.dbc starts here";
CM_ "Imported file _bosch_2018.dbc starts here"
VERSION
CM_ "honda_civic_hatchback_ex_2017_can.dbc sta";
CM_ "honda_civic_hatchback_ex_2017_can.dbc star
CM_ "honda_civic_hatchback_ex_2017_can.dbc star";
CM_ "honda_civic_hatchback_ex_2017_can.dbc start
CM_ "honda_civic_hatchback_ex_2017_can.dbc star";
CM_ "honda_civic_hatchback_ex_2017_can.dbc start
CM_ "honda_civic_hatchback_ex_2017_can.dbc start";
CM_ "honda_civic_hatchback_ex_2017_can.dbc starts
CM_ "honda_civic_hatchback_ex_2017_can.dbc sta";
CM_ "honda_civic_hatchback_ex_2017_can.dbc star
CM_ "honda_civic_hatchback_ex_2017_can.dbc star";
CM_ "honda_civic_hatchback_ex_2017_can.dbc start
CM_ "honda_civic_hatchback_ex_2017_can.dbc star";
CM_ "honda_civic_hatchback_ex_2017_can.dbc start
CM_ "honda_civic_hatchback_ex_2017_can.dbc start";
CM_ "honda_civic_hatchback_ex_2017_can.dbc starts
CM_ "honda_civic_hatchback_ex_2017_can.dbc star";
CM_ "honda_civic_hatchback_ex_2017_can.dbc start
CM_ "honda_civic_hatchback_ex_2017_can.dbc start";
CM_ "honda_civic_hatchback_ex_2017_can.dbc starts
CM_ "honda_civic_hatchback_ex_2017_can.dbc star";
CM_ "honda_civic_hatchback_ex_2017_can.dbc start
CM_ "honda_civic_hatchback_ex_2017_can.dbc start";
CM_ "honda_civic_hatchback_ex_2017_can.dbc starts
CM_ "honda_civic_hatchback_ex_2017_can.dbc start";
CM_ "honda_civic_hatchback_ex_2017_can.dbc starts
CM_ "honda_civic_hatchback_ex_2017_can.dbc start";
CM_ "honda_civic_hatchback_ex_2017_can.dbc starts
CM_ "honda_civic_hatchback_ex_2017_can.dbc starts";
CM_ "honda_civic_hatchback_ex_2017_can.dbc starts
CM_ "honda_civic_hatchback_ex_2017_can.dbc starts ";
CM_ "honda_civic_hatchback_ex_2017_can.dbc starts h
CM_ "honda_civic_hatchback_ex_2017_can.dbc star";
CM_ "honda_civic_hatchback_ex_2017_can.dbc start
CM_ "honda_civic_hatchback_ex_2017_can.dbc start";
CM_ "honda_civic_hatchback_ex_2017_can.dbc starts
CM_ "honda_civic_hatchback_ex_2017_can.dbc star";
CM_ "honda_civic_hatchback_ex_2017_can.dbc start
CM_ "honda_civic_hatchback_ex_2017_can.dbc start";
CM_ "honda_civic_hatchback_ex_2017_can.dbc starts
CM_ "honda_civic_hatchback_ex_2017_can.dbc start";
CM_ "honda_civic_hatchback_ex_2017_can.dbc starts
CM_ "honda_civic_hatchback_ex_2017_can.dbc start";
CM_ "honda_civic_hatchback_ex_2017_can.dbc starts
CM_ "honda_civic_hatchback_ex_2017_can.dbc starts";
CM_ "honda_civic_hatchback_ex_2017_can.dbc starts
CM_ "honda_civic_hatchback_ex_2017_can.dbc starts ";
CM_ "honda_civic_hatchback_ex_2017_can.dbc starts h
CM_ "honda_civic_hatchback_ex_2017_can.dbc start";
CM_ "honda_civic_hatchback_ex_2017_can.dbc starts
CM_ "honda_civic_hatchback_ex_2017_can.dbc start";
CM_ "honda_civic_hatchback_ex_2017_can.dbc starts
CM_ "honda_civic_hatchback_ex_2017_can.dbc starts";
CM_ "honda_civic_hatchback_ex_2017_can.dbc starts
CM_ "honda_civic_hatchback_ex_2017_can.dbc starts ";
CM_ "honda_civic_hatchback_ex_2017_can.dbc starts h
CM_ "honda_civic_hatchback_ex_2017_can.dbc starts";
CM_ "honda_civic_hatchback_ex_2017_can.dbc starts
CM_ "honda_civic_hatchback_ex_2017_can.dbc starts ";
CM_ "honda_civic_hatchback_ex_2017_can.dbc starts h
CM_ "honda_civic_hatchback_ex_2017_can.dbc starts ";
CM_ "honda_civic_hatchback_ex_2017_can.dbc starts h
CM_ "honda_civic_hatchback_ex_2017_can.dbc starts h";
CM_ "honda_civic_hatchback_ex_2017_can.dbc starts he
CM_ "honda_civic_hatchback_ex_2017_can.dbc star";
CM_ "honda_civic_hatchback_ex_2017_can.dbc start
CM_ "honda_civic_hatchback_ex_2017_can.dbc start";
CM_ "honda_civic_hatchback_ex_2017_can.dbc starts
CM_ "honda_civic_hatchback_ex_2017_can.dbc star";
CM_ "honda_civic_hatchback_ex_2017_can.dbc start
CM_ "honda_civic_hatchback_ex_2017_can.dbc start";
CM_ "honda_civic_hatchback_ex_2017_can.dbc starts
CM_ "honda_civic_hatchback_ex_2017_can.dbc start";
CM_ "honda_civic_hatchback_ex_2017_can.dbc starts
CM_ "honda_civic_hatchback_ex_2017_can.dbc start";
CM_ "honda_civic_hatchback_ex_2017_can.dbc starts
CM_ "honda_civic_hatchback_ex_2017_can.dbc starts";
CM_ "honda_civic_hatchback_ex_2017_can.dbc starts
CM_ "honda_civic_hatchback_ex_2017_can.dbc starts ";
CM_ "honda_civic_hatchback_ex_2017_can.dbc starts h
CM_ "honda_civic_hatchback_ex_2017_can.dbc start";
CM_ "honda_civic_hatchback_ex_2017_can.dbc starts
CM_ "honda_civic_hatchback_ex_2017_can.dbc start";
CM_ "honda_civic_hatchback_ex_2017_can.dbc starts
CM_ "honda_civic_hatchback_ex_2017_can.dbc starts";
CM_ "honda_civic_hatchback_ex_2017_can.dbc starts
CM_ "honda_civic_hatchback_ex_2017_can.dbc starts ";
CM_ "honda_civic_hatchback_ex_2017_can.dbc starts h
CM_ "honda_civic_hatchback_ex_2017_can.dbc starts";
CM_ "honda_civic_hatchback_ex_2017_can.dbc starts
CM_ "honda_civic_hatchback_ex_2017_can.dbc starts ";
CM_ "honda_civic_hatchback_ex_2017_can.dbc starts h
CM_ "honda_civic_hatchback_ex_2017_can.dbc starts ";
CM_ "honda_civic_hatchback_ex_2017_can.dbc starts h
CM_ "honda_civic_hatchback_ex_2017_can.dbc starts h";
CM_ "honda_civic_hatchback_ex_2017_can.dbc starts he
CM_ "honda_civic_hatchback_ex_2017_can.dbc start";
CM_ "honda_civic_hatchback_ex_2017_can.dbc starts
CM_ "honda_civic_hatchback_ex_2017_can.dbc start";
CM_ "honda_civic_hatchback_ex_2017_can.dbc starts
CM_ "honda_civic_hatchback_ex_2017_can.dbc starts";
CM_ "honda_civic_hatchback_ex_2017_can.dbc starts
CM_ "honda_civic_hatchback_ex_2017_can.dbc starts ";
CM_ "honda_civic_hatchback_ex_2017_can.dbc starts h
CM_ "honda_civic_hatchback_ex_2017_can.dbc starts";
CM_ "honda_civic_hatchback_ex_2017_can.dbc starts
CM_ "honda_civic_hatchback_ex_2017_can.dbc starts ";
CM_ "honda_civic_hatchback_ex_2017_can.dbc starts h
CM_ "honda_civic_hatchback_ex_2017_can.dbc starts ";
CM_ "honda_civic_hatchback_ex_2017_can.dbc starts h
CM_ "honda_civic_hatchback_ex_2017_can.dbc starts h";
CM_ "honda_civic_hatchback_ex_2017_can.dbc starts he
CM_ "honda_civic_hatchback_ex_2017_can.dbc starts";
CM_ "honda_civic_hatchback_ex_2017_can.dbc starts
CM_ "honda_civic_hatchback_ex_2017_can.dbc starts ";
CM_ "honda_civic_hatchback_ex_2017_can.dbc starts h
CM_ "honda_civic_hatchback_ex_2017_can.dbc starts ";
CM_ "honda_civic_hatchback_ex_2017_can.dbc starts h
CM_ "honda_civic_hatchback_ex_2017_can.dbc starts h";
CM_ "honda_civic_hatchback_ex_2017_can.dbc starts he
CM_ "honda_civic_hatchback_ex_2017_can.dbc starts ";
CM_ "honda_civic_hatchback_ex_2017_can.dbc starts h
CM_ "honda_civic_hatchback_ex_2017_can.dbc starts h";
CM_ "honda_civic_hatchback_ex_2017_can.dbc starts he
CM_ "honda_civic_hatchback_ex_2017_can.dbc starts h";
CM_ "honda_civic_hatchback_ex_2017_can.dbc starts he
CM_ "honda_civic_hatchback_ex_2017_can.dbc starts he";
CM_ "honda_civic_hatchback_ex_2017_can.dbc starts her
CM_ "honda_civic_hatchback_ex_2017_can.dbc star";
CM_ "honda_civic_hatchback_ex_2017_can.dbc start
CM_ "honda_civic_hatchback_ex_2017_can.dbc start";
CM_ "honda_civic_hatchback_ex_2017_can.dbc starts
CM_ "honda_civic_hatchback_ex_2017_can.dbc star";
CM_ "honda_civic_hatchback_ex_2017_can.dbc start
CM_ "honda_civic_hatchback_ex_2017_can.dbc start";
CM_ "honda_civic_hatchback_ex_2017_can.dbc starts
CM_ "honda_civic_hatchback_ex_2017_can.dbc start";
CM_ "honda_civic_hatchback_ex_2017_can.dbc starts
CM_ "honda_civic_hatchback_ex_2017_can.dbc start";
CM_ "honda_civic_hatchback_ex_2017_can.dbc starts
CM_ "honda_civic_hatchback_ex_2017_can.dbc starts";
CM_ "honda_civic_hatchback_ex_2017_can.dbc starts
CM_ "honda_civic_hatchback_ex_2017_can.dbc starts ";
CM_ "honda_civic_hatchback_ex_2017_can.dbc starts h
CM_ "honda_civic_hatchback_ex_2017_can.dbc start";
CM_ "honda_civic_hatchback_ex_2017_can.dbc starts
CM_ "honda_civic_hatchback_ex_2017_can.dbc start";
CM_ "honda_civic_hatchback_ex_2017_can.dbc starts
CM_ "honda_civic_hatchback_ex_2017_can.dbc starts";
CM_ "honda_civic_hatchback_ex_2017_can.dbc starts
CM_ "honda_civic_hatchback_ex_2017_can.dbc starts ";
CM_ "honda_civic_hatchback_ex_2017_can.dbc starts h
CM_ "honda_civic_hatchback_ex_2017_can.dbc starts";
CM_ "honda_civic_hatchback_ex_2017_can.dbc starts
CM_ "honda_civic_hatchback_ex_2017_can.dbc starts ";
CM_ "honda_civic_hatchback_ex_2017_can.dbc starts h
CM_ "honda_civic_hatchback_ex_2017_can.dbc starts ";
CM_ "honda_civic_hatchback_ex_2017_can.dbc starts h
CM_ "honda_civic_hatchback_ex_2017_can.dbc starts h";
CM_ "honda_civic_hatchback_ex_2017_can.dbc starts he
CM_ "honda_civic_hatchback_ex_2017_can.dbc start";
CM_ "honda_civic_hatchback_ex_2017_can.dbc starts
CM_ "honda_civic_hatchback_ex_2017_can.dbc start";
CM_ "honda_civic_hatchback_ex_2017_can.dbc starts
CM_ "honda_civic_hatchback_ex_2017_can.dbc starts";
CM_ "honda_civic_hatchback_ex_2017_can.dbc starts
CM_ "honda_civic_hatchback_ex_2017_can.dbc starts ";
CM_ "honda_civic_hatchback_ex_2017_can.dbc starts h
CM_ "honda_civic_hatchback_ex_2017_can.dbc starts";
CM_ "honda_civic_hatchback_ex_2017_can.dbc starts
CM_ "honda_civic_hatchback_ex_2017_can.dbc starts ";
CM_ "honda_civic_hatchback_ex_2017_can.dbc starts h
CM_ "honda_civic_hatchback_ex_2017_can.dbc starts ";
CM_ "honda_civic_hatchback_ex_2017_can.dbc starts h
CM_ "honda_civic_hatchback_ex_2017_can.dbc starts h";
CM_ "honda_civic_hatchback_ex_2017_can.dbc starts he
CM_ "honda_civic_hatchback_ex_2017_can.dbc starts";
CM_ "honda_civic_hatchback_ex_2017_can.dbc starts
CM_ "honda_civic_hatchback_ex_2017_can.dbc starts ";
CM_ "honda_civic_hatchback_ex_2017_can.dbc starts h
CM_ "honda_civic_hatchback_ex_2017_can.dbc starts ";
CM_ "honda_civic_hatchback_ex_2017_can.dbc starts h
CM_ "honda_civic_hatchback_ex_2017_can.dbc starts h";
CM_ "honda_civic_hatchback_ex_2017_can.dbc starts he
CM_ "honda_civic_hatchback_ex_2017_can.dbc starts ";
CM_ "honda_civic_hatchback_ex_2017_can.dbc starts h
CM_ "honda_civic_hatchback_ex_2017_can.dbc starts h";
CM_ "honda_civic_hatchback_ex_2017_can.dbc starts he
CM_ "honda_civic_hatchback_ex_2017_can.dbc starts h";
CM_ "honda_civic_hatchback_ex_2017_can.dbc starts he
CM_ "honda_civic_hatchback_ex_2017_can.dbc starts he";
CM_ "honda_civic_hatchback_ex_2017_can.dbc starts her
CM_ "honda_civic_hatchback_ex_2017_can.dbc start";
CM_ "honda_civic_hatchback_ex_2017_can.dbc starts
CM_ "honda_civic_hatchback_ex_2017_can.dbc start";
CM_ "honda_civic_hatchback_ex_2017_can.dbc starts
CM_ "honda_civic_hatchback_ex_2017_can.dbc starts";
CM_ "honda_civic_hatchback_ex_2017_can.dbc starts
CM_ "honda_civic_hatchback_ex_2017_can.dbc starts ";
CM_ "honda_civic_hatchback_ex_2017_can.dbc starts h
CM_ "honda_civic_hatchback_ex_2017_can.dbc starts";
CM_ "honda_civic_hatchback_ex_2017_can.dbc starts
CM_ "honda_civic_hatchback_ex_2017_can.dbc starts ";
CM_ "honda_civic_hatchback_ex_2017_can.dbc starts h
CM_ "honda_civic_hatchback_ex_2017_can.dbc starts ";
CM_ "honda_civic_hatchback_ex_2017_can.dbc starts h
CM_ "honda_civic_hatchback_ex_2017_can.dbc starts h";
CM_ "honda_civic_hatchback_ex_2017_can.dbc starts he
CM_ "honda_civic_hatchback_ex_2017_can.dbc starts";
CM_ "honda_civic_hatchback_ex_2017_can.dbc starts
CM_ "honda_civic_hatchback_ex_2017_can.dbc starts ";
CM_ "honda_civic_hatchback_ex_2017_can.dbc starts h
CM_ "honda_civic_hatchback_ex_2017_can.dbc starts ";
CM_ "honda_civic_hatchback_ex_2017_can.dbc starts h
CM_ "honda_civic_hatchback_ex_2017_can.dbc starts h";
CM_ "honda_civic_hatchback_ex_2017_can.dbc starts he
CM_ "honda_civic_hatchback_ex_2017_can.dbc starts ";
CM_ "honda_civic_hatchback_ex_2017_can.dbc starts h
CM_ "honda_civic_hatchback_ex_2017_can.dbc starts h";
CM_ "honda_civic_hatchback_ex_2017_can.dbc starts he
CM_ "honda_civic_hatchback_ex_2017_can.dbc starts h";
CM_ "honda_civic_hatchback_ex_2017_can.dbc starts he
CM_ "honda_civic_hatchback_ex_2017_can.dbc starts he";
CM_ "honda_civic_hatchback_ex_2017_can.dbc starts her
CM_ "honda_civic_hatchback_ex_2017_can.dbc starts";
CM_ "honda_civic_hatchback_ex_2017_can.dbc starts
CM_ "honda_civic_hatchback_ex_2017_can.dbc starts ";
CM_ "honda_civic_hatchback_ex_2017_can.dbc starts h
CM_ "honda_civic_hatchback_ex_2017_can.dbc starts ";
CM_ "honda_civic_hatchback_ex_2017_can.dbc starts h
CM_ "honda_civic_hatchback_ex_2017_can.dbc starts h";
CM_ "honda_civic_hatchback_ex_2017_can.dbc starts he
CM_ "honda_civic_hatchback_ex_2017_can.dbc starts ";
CM_ "honda_civic_hatchback_ex_2017_can.dbc starts h
CM_ "honda_civic_hatchback_ex_2017_can.dbc starts h";
CM_ "honda_civic_hatchback_ex_2017_can.dbc starts he
CM_ "honda_civic_hatchback_ex_2017_can.dbc starts h";
CM_ "honda_civic_hatchback_ex_2017_can.dbc starts he
CM_ "honda_civic_hatchback_ex_2017_can.dbc starts he";
CM_ "honda_civic_hatchback_ex_2017_can.dbc starts her
CM_ "honda_civic_hatchback_ex_2017_can.dbc starts ";
CM_ "honda_civic_hatchback_ex_2017_can.dbc starts h
CM_ "honda_civic_hatchback_ex_2017_can.dbc starts h";
CM_ "honda_civic_hatchback_ex_2017_can.dbc starts he
CM_ "honda_civic_hatchback_ex_2017_can.dbc starts h";
CM_ "honda_civic_hatchback_ex_2017_can.dbc starts he
CM_ "honda_civic_hatchback_ex_2017_can.dbc starts he";
CM_ "honda_civic_hatchback_ex_2017_can.dbc starts her
CM_ "honda_civic_hatchback_ex_2017_can.dbc starts h";
CM_ "honda_civic_hatchback_ex_2017_can.dbc starts he
CM_ "honda_civic_hatchback_ex_2017_can.dbc starts he";
CM_ "honda_civic_hatchback_ex_2017_can.dbc starts her
CM_ "honda_civic_hatchback_ex_2017_can.dbc starts he";
CM_ "honda_civic_hatchback_ex_2017_can.dbc starts her
CM_ "honda_civic_hatchback_ex_2017_can.dbc starts her";
CM_ "honda_civic_hatchback_ex_2017_can.dbc starts here
CM_ "honda_civic_hatchback_ex_2017_can.dbc star";
CM_ "honda_civic_hatchback_ex_2017_can.dbc start
CM_ "honda_civic_hatchback_ex_2017_can.dbc start";
CM_ "honda_civic_hatchback_ex_2017_can.dbc starts
CM_ "honda_civic_hatchback_ex_2017_can.dbc star";
CM_ "honda_civic_hatchback_ex_2017_can.dbc start
CM_ "honda_civic_hatchback_ex_2017_can.dbc start";
CM_ "honda_civic_hatchback_ex_2017_can.dbc starts
CM_ "honda_civic_hatchback_ex_2017_can.dbc start";
CM_ "honda_civic_hatchback_ex_2017_can.dbc starts
CM_ "honda_civic_hatchback_ex_2017_can.dbc start";
CM_ "honda_civic_hatchback_ex_2017_can.dbc starts
CM_ "honda_civic_hatchback_ex_2017_can.dbc starts";
CM_ "honda_civic_hatchback_ex_2017_can.dbc starts
CM_ "honda_civic_hatchback_ex_2017_can.dbc starts ";
CM_ "honda_civic_hatchback_ex_2017_can.dbc starts h
CM_ "honda_civic_hatchback_ex_2017_can.dbc start";
CM_ "honda_civic_hatchback_ex_2017_can.dbc starts
CM_ "honda_civic_hatchback_ex_2017_can.dbc start";
CM_ "honda_civic_hatchback_ex_2017_can.dbc starts
CM_ "honda_civic_hatchback_ex_2017_can.dbc starts";
CM_ "honda_civic_hatchback_ex_2017_can.dbc starts
CM_ "honda_civic_hatchback_ex_2017_can.dbc starts ";
CM_ "honda_civic_hatchback_ex_2017_can.dbc starts h
CM_ "honda_civic_hatchback_ex_2017_can.dbc starts";
CM_ "honda_civic_hatchback_ex_2017_can.dbc starts
CM_ "honda_civic_hatchback_ex_2017_can.dbc starts ";
CM_ "honda_civic_hatchback_ex_2017_can.dbc starts h
CM_ "honda_civic_hatchback_ex_2017_can.dbc starts ";
CM_ "honda_civic_hatchback_ex_2017_can.dbc starts h
CM_ "honda_civic_hatchback_ex_2017_can.dbc starts h";
CM_ "honda_civic_hatchback_ex_2017_can.dbc starts he
CM_ "honda_civic_hatchback_ex_2017_can.dbc start";
CM_ "honda_civic_hatchback_ex_2017_can.dbc starts
CM_ "honda_civic_hatchback_ex_2017_can.dbc start";
CM_ "honda_civic_hatchback_ex_2017_can.dbc starts
CM_ "honda_civic_hatchback_ex_2017_can.dbc starts";
CM_ "honda_civic_hatchback_ex_2017_can.dbc starts
CM_ "honda_civic_hatchback_ex_2017_can.dbc starts ";
CM_ "honda_civic_hatchback_ex_2017_can.dbc starts h
CM_ "honda_civic_hatchback_ex_2017_can.dbc starts";
CM_ "honda_civic_hatchback_ex_2017_can.dbc starts
CM_ "honda_civic_hatchback_ex_2017_can.dbc starts ";
CM_ "honda_civic_hatchback_ex_2017_can.dbc starts h
CM_ "honda_civic_hatchback_ex_2017_can.dbc starts ";
CM_ "honda_civic_hatchback_ex_2017_can.dbc starts h
CM_ "honda_civic_hatchback_ex_2017_can.dbc starts h";
CM_ "honda_civic_hatchback_ex_2017_can.dbc starts he
CM_ "honda_civic_hatchback_ex_2017_can.dbc starts";
CM_ "honda_civic_hatchback_ex_2017_can.dbc starts
CM_ "honda_civic_hatchback_ex_2017_can.dbc starts ";
CM_ "honda_civic_hatchback_ex_2017_can.dbc starts h
CM_ "honda_civic_hatchback_ex_2017_can.dbc starts ";
CM_ "honda_civic_hatchback_ex_2017_can.dbc starts h
CM_ "honda_civic_hatchback_ex_2017_can.dbc starts h";
CM_ "honda_civic_hatchback_ex_2017_can.dbc starts he
CM_ "honda_civic_hatchback_ex_2017_can.dbc starts ";
CM_ "honda_civic_hatchback_ex_2017_can.dbc starts h
CM_ "honda_civic_hatchback_ex_2017_can.dbc starts h";
CM_ "honda_civic_hatchback_ex_2017_can.dbc starts he
CM_ "honda_civic_hatchback_ex_2017_can.dbc starts h";
CM_ "honda_civic_hatchback_ex_2017_can.dbc starts he
CM_ "honda_civic_hatchback_ex_2017_can.dbc starts he";
CM_ "honda_civic_hatchback_ex_2017_can.dbc starts her
CM_ "honda_civic_hatchback_ex_2017_can.dbc start";
CM_ "honda_civic_hatchback_ex_2017_can.dbc starts
CM_ "honda_civic_hatchback_ex_2017_can.dbc start";
CM_ "honda_civic_hatchback_ex_2017_can.dbc starts
CM_ "honda_civic_hatchback_ex_2017_can.dbc starts";
CM_ "honda_civic_hatchback_ex_2017_can.dbc starts
CM_ "honda_civic_hatchback_ex_2017_can.dbc starts ";
CM_ "honda_civic_hatchback_ex_2017_can.dbc starts h
CM_ "honda_civic_hatchback_ex_2017_can.dbc starts";
CM_ "honda_civic_hatchback_ex_2017_can.dbc starts
CM_ "honda_civic_hatchback_ex_2017_can.dbc starts ";
CM_ "honda_civic_hatchback_ex_2017_can.dbc starts h
CM_ "honda_civic_hatchback_ex_2017_can.dbc starts ";
CM_ "honda_civic_hatchback_ex_2017_can.dbc starts h
CM_ "honda_civic_hatchback_ex_2017_can.dbc starts h";
CM_ "honda_civic_hatchback_ex_2017_can.dbc starts he
CM_ "honda_civic_hatchback_ex_2017_can.dbc starts";
CM_ "honda_civic_hatchback_ex_2017_can.dbc starts
CM_ "honda_civic_hatchback_ex_2017_can.dbc starts ";
CM_ "honda_civic_hatchback_ex_2017_can.dbc starts h
CM_ "honda_civic_hatchback_ex_2017_can.dbc starts ";
CM_ "honda_civic_hatchback_ex_2017_can.dbc starts h
CM_ "honda_civic_hatchback_ex_2017_can.dbc starts h";
CM_ "honda_civic_hatchback_ex_2017_can.dbc starts he
CM_ "honda_civic_hatchback_ex_2017_can.dbc starts ";
CM_ "honda_civic_hatchback_ex_2017_can.dbc starts h
CM_ "honda_civic_hatchback_ex_2017_can.dbc starts h";
CM_ "honda_civic_hatchback_ex_2017_can.dbc starts he
CM_ "honda_civic_hatchback_ex_2017_can.dbc starts h";
CM_ "honda_civic_hatchback_ex_2017_can.dbc starts he
CM_ "honda_civic_hatchback_ex_2017_can.dbc starts he";
CM_ "honda_civic_hatchback_ex_2017_can.dbc starts her
CM_ "honda_civic_hatchback_ex_2017_can.dbc starts";
CM_ "honda_civic_hatchback_ex_2017_can.dbc starts
CM_ "honda_civic_hatchback_ex_2017_can.dbc starts ";
CM_ "honda_civic_hatchback_ex_2017_can.dbc starts h
CM_ "honda_civic_hatchback_ex_2017_can.dbc starts ";
CM_ "honda_civic_hatchback_ex_2017_can.dbc starts h
CM_ "honda_civic_hatchback_ex_2017_can.dbc starts h";
CM_ "honda_civic_hatchback_ex_2017_can.dbc starts he
CM_ "honda_civic_hatchback_ex_2017_can.dbc starts ";
CM_ "honda_civic_hatchback_ex_2017_can.dbc starts h
CM_ "honda_civic_hatchback_ex_2017_can.dbc starts h";
CM_ "honda_civic_hatchback_ex_2017_can.dbc starts he
CM_ "honda_civic_hatchback_ex_2017_can.dbc starts h";
CM_ "honda_civic_hatchback_ex_2017_can.dbc starts he
CM_ "honda_civic_hatchback_ex_2017_can.dbc starts he";
CM_ "honda_civic_hatchback_ex_2017_can.dbc starts her
CM_ "honda_civic_hatchback_ex_2017_can.dbc starts ";
CM_ "honda_civic_hatchback_ex_2017_can.dbc starts h
CM_ "honda_civic_hatchback_ex_2017_can.dbc starts h";
CM_ "honda_civic_hatchback_ex_2017_can.dbc starts he
CM_ "honda_civic_hatchback_ex_2017_can.dbc starts h";
CM_ "honda_civic_hatchback_ex_2017_can.dbc starts he
CM_ "honda_civic_hatchback_ex_2017_can.dbc starts he";
CM_ "honda_civic_hatchback_ex_2017_can.dbc starts her
CM_ "honda_civic_hatchback_ex_2017_can.dbc starts h";
CM_ "honda_civic_hatchback_ex_2017_can.dbc starts he
CM_ "honda_civic_hatchback_ex_2017_can.dbc starts he";
CM_ "honda_civic_hatchback_ex_2017_can.dbc starts her
CM_ "honda_civic_hatchback_ex_2017_can.dbc starts he";
CM_ "honda_civic_hatchback_ex_2017_can.dbc starts her
CM_ "honda_civic_hatchback_ex_2017_can.dbc starts her";
CM_ "honda_civic_hatchback_ex_2017_can.dbc starts here
CM_ "honda_civic_hatchback_ex_2017_can.dbc start";
CM_ "honda_civic_hatchback_ex_2017_can.dbc starts
CM_ "honda_civic_hatchback_ex_2017_can.dbc start";
CM_ "honda_civic_hatchback_ex_2017_can.dbc starts
CM_ "honda_civic_hatchback_ex_2017_can.dbc starts";
CM_ "honda_civic_hatchback_ex_2017_can.dbc starts
CM_ "honda_civic_hatchback_ex_2017_can.dbc starts ";
CM_ "honda_civic_hatchback_ex_2017_can.dbc starts h
CM_ "honda_civic_hatchback_ex_2017_can.dbc starts";
CM_ "honda_civic_hatchback_ex_2017_can.dbc starts
CM_ "honda_civic_hatchback_ex_2017_can.dbc starts ";
CM_ "honda_civic_hatchback_ex_2017_can.dbc starts h
CM_ "honda_civic_hatchback_ex_2017_can.dbc starts ";
CM_ "honda_civic_hatchback_ex_2017_can.dbc starts h
CM_ "honda_civic_hatchback_ex_2017_can.dbc starts h";
CM_ "honda_civic_hatchback_ex_2017_can.dbc starts he
CM_ "honda_civic_hatchback_ex_2017_can.dbc starts";
CM_ "honda_civic_hatchback_ex_2017_can.dbc starts
CM_ "honda_civic_hatchback_ex_2017_can.dbc starts ";
CM_ "honda_civic_hatchback_ex_2017_can.dbc starts h
CM_ "honda_civic_hatchback_ex_2017_can.dbc starts ";
CM_ "honda_civic_hatchback_ex_2017_can.dbc starts h
CM_ "honda_civic_hatchback_ex_2017_can.dbc starts h";
CM_ "honda_civic_hatchback_ex_2017_can.dbc starts he
CM_ "honda_civic_hatchback_ex_2017_can.dbc starts ";
CM_ "honda_civic_hatchback_ex_2017_can.dbc starts h
CM_ "honda_civic_hatchback_ex_2017_can.dbc starts h";
CM_ "honda_civic_hatchback_ex_2017_can.dbc starts he
CM_ "honda_civic_hatchback_ex_2017_can.dbc starts h";
CM_ "honda_civic_hatchback_ex_2017_can.dbc starts he
CM_ "honda_civic_hatchback_ex_2017_can.dbc starts he";
CM_ "honda_civic_hatchback_ex_2017_can.dbc starts her
CM_ "honda_civic_hatchback_ex_2017_can.dbc starts";
CM_ "honda_civic_hatchback_ex_2017_can.dbc starts
CM_ "honda_civic_hatchback_ex_2017_can.dbc starts ";
CM_ "honda_civic_hatchback_ex_2017_can.dbc starts h
CM_ "honda_civic_hatchback_ex_2017_can.dbc starts ";
CM_ "honda_civic_hatchback_ex_2017_can.dbc starts h
CM_ "honda_civic_hatchback_ex_2017_can.dbc starts h";
CM_ "honda_civic_hatchback_ex_2017_can.dbc starts he
CM_ "honda_civic_hatchback_ex_2017_can.dbc starts ";
CM_ "honda_civic_hatchback_ex_2017_can.dbc starts h
CM_ "honda_civic_hatchback_ex_2017_can.dbc starts h";
CM_ "honda_civic_hatchback_ex_2017_can.dbc starts he
CM_ "honda_civic_hatchback_ex_2017_can.dbc starts h";
CM_ "honda_civic_hatchback_ex_2017_can.dbc starts he
CM_ "honda_civic_hatchback_ex_2017_can.dbc starts he";
CM_ "honda_civic_hatchback_ex_2017_can.dbc starts her
CM_ "honda_civic_hatchback_ex_2017_can.dbc starts ";
CM_ "honda_civic_hatchback_ex_2017_can.dbc starts h
CM_ "honda_civic_hatchback_ex_2017_can.dbc starts h";
CM_ "honda_civic_hatchback_ex_2017_can.dbc starts he
CM_ "honda_civic_hatchback_ex_2017_can.dbc starts h";
CM_ "honda_civic_hatchback_ex_2017_can.dbc starts he
CM_ "honda_civic_hatchback_ex_2017_can.dbc starts he";
CM_ "honda_civic_hatchback_ex_2017_can.dbc starts her
CM_ "honda_civic_hatchback_ex_2017_can.dbc starts h";
CM_ "honda_civic_hatchback_ex_2017_can.dbc starts he
CM_ "honda_civic_hatchback_ex_2017_can.dbc starts he";
CM_ "honda_civic_hatchback_ex_2017_can.dbc starts her
CM_ "honda_civic_hatchback_ex_2017_can.dbc starts he";
CM_ "honda_civic_hatchback_ex_2017_can.dbc starts her
CM_ "honda_civic_hatchback_ex_2017_can.dbc starts her";
CM_ "honda_civic_hatchback_ex_2017_can.dbc starts here
CM_ "honda_civic_hatchback_ex_2017_can.dbc starts";
CM_ "honda_civic_hatchback_ex_2017_can.dbc starts
CM_ "honda_civic_hatchback_ex_2017_can.dbc starts ";
CM_ "honda_civic_hatchback_ex_2017_can.dbc starts h
CM_ "honda_civic_hatchback_ex_2017_can.dbc starts ";
CM_ "honda_civic_hatchback_ex_2017_can.dbc starts h
CM_ "honda_civic_hatchback_ex_2017_can.dbc starts h";
CM_ "honda_civic_hatchback_ex_2017_can.dbc starts he
CM_ "honda_civic_hatchback_ex_2017_can.dbc starts ";
CM_ "honda_civic_hatchback_ex_2017_can.dbc starts h
CM_ "honda_civic_hatchback_ex_2017_can.dbc starts h";
CM_ "honda_civic_hatchback_ex_2017_can.dbc starts he
CM_ "honda_civic_hatchback_ex_2017_can.dbc starts h";
CM_ "honda_civic_hatchback_ex_2017_can.dbc starts he
CM_ "honda_civic_hatchback_ex_2017_can.dbc starts he";
CM_ "honda_civic_hatchback_ex_2017_can.dbc starts her
CM_ "honda_civic_hatchback_ex_2017_can.dbc starts ";
CM_ "honda_civic_hatchback_ex_2017_can.dbc starts h
CM_ "honda_civic_hatchback_ex_2017_can.dbc starts h";
CM_ "honda_civic_hatchback_ex_2017_can.dbc starts he
CM_ "honda_civic_hatchback_ex_2017_can.dbc starts h";
CM_ "honda_civic_hatchback_ex_2017_can.dbc starts he
CM_ "honda_civic_hatchback_ex_2017_can.dbc starts he";
CM_ "honda_civic_hatchback_ex_2017_can.dbc starts her
CM_ "honda_civic_hatchback_ex_2017_can.dbc starts h";
CM_ "honda_civic_hatchback_ex_2017_can.dbc starts he
CM_ "honda_civic_hatchback_ex_2017_can.dbc starts he";
CM_ "honda_civic_hatchback_ex_2017_can.dbc starts her
CM_ "honda_civic_hatchback_ex_2017_can.dbc starts he";
CM_ "honda_civic_hatchback_ex_2017_can.dbc starts her
CM_ "honda_civic_hatchback_ex_2017_can.dbc starts her";
CM_ "honda_civic_hatchback_ex_2017_can.dbc starts here
CM_ "honda_civic_hatchback_ex_2017_can.dbc starts ";
CM_ "honda_civic_hatchback_ex_2017_can.dbc starts h
CM_ "honda_civic_hatchback_ex_2017_can.dbc starts h";
CM_ "honda_civic_hatchback_ex_2017_can.dbc starts he
CM_ "honda_civic_hatchback_ex_2017_can.dbc starts h";
CM_ "honda_civic_hatchback_ex_2017_can.dbc starts he
CM_ "honda_civic_hatchback_ex_2017_can.dbc starts he";
CM_ "honda_civic_hatchback_ex_2017_can.dbc starts her
CM_ "honda_civic_hatchback_ex_2017_can.dbc starts h";
CM_ "honda_civic_hatchback_ex_2017_can.dbc starts he
CM_ "honda_civic_hatchback_ex_2017_can.dbc starts he";
CM_ "honda_civic_hatchback_ex_2017_can.dbc starts her
CM_ "honda_civic_hatchback_ex_2017_can.dbc starts he";
CM_ "honda_civic_hatchback_ex_2017_can.dbc starts her
CM_ "honda_civic_hatchback_ex_2017_can.dbc starts her";
CM_ "honda_civic_hatchback_ex_2017_can.dbc starts here
CM_ "honda_civic_hatchback_ex_2017_can.dbc starts h";
CM_ "honda_civic_hatchback_ex_2017_can.dbc starts he
CM_ "honda_civic_hatchback_ex_2017_can.dbc starts he";
CM_ "honda_civic_hatchback_ex_2017_can.dbc starts her
CM_ "honda_civic_hatchback_ex_2017_can.dbc starts he";
CM_ "honda_civic_hatchback_ex_2017_can.dbc starts her
CM_ "honda_civic_hatchback_ex_2017_can.dbc starts her";
CM_ "honda_civic_hatchback_ex_2017_can.dbc starts here
CM_ "honda_civic_hatchback_ex_2017_can.dbc starts he";
CM_ "honda_civic_hatchback_ex_2017_can.dbc starts her
CM_ "honda_civic_hatchback_ex_2017_can.dbc starts her";
CM_ "honda_civic_hatchback_ex_2017_can.dbc starts here
CM_ "honda_civic_hatchback_ex_2017_can.dbc starts her";
CM_ "honda_civic_hatchback_ex_2017_can.dbc starts here
CM_ "honda_civic_hatchback_ex_2017_can.dbc starts here";
CM_ "honda_civic_hatchback_ex_2017_can.dbc starts here"
BO_ 401 GEARBOX: 8 PCM
SG_ GEAR_SHIFTER : 5|6@0+ (1,0) [0|63]
CM_ "CHFFR_METRIC 330 STEER_ANGLE STEER_ANGLE 0.36 180; CHFFR_METRIC 380 ENGINE_RPM ENGINE_RPM 1 0; CHFFR_METRIC 804 ENGINE_TEMPERATURE ENGINE_TEMPERATUR";
CM_ "CHFFR_METRIC 330 STEER_ANGLE STEER_ANGLE 0.36 180; CHFFR_METRIC 380 ENGINE_RPM ENGINE_RPM 1 0; CHFFR_METRIC 804 ENGINE_TEMPERATURE ENGINE_TEMPERATURE
CM_ "CHFFR_METRIC 330 STEER_ANGLE STEER_ANGLE 0.36 180; CHFFR_METRIC 380 ENGINE_RPM ENGINE_RPM 1 0; CHFFR_METRIC 804 ENGINE_TEMPERATURE ENGINE_TEMPERATUR";
CM_ "CHFFR_METRIC 330 STEER_ANGLE STEER_ANGLE 0.36 180; CHFFR_METRIC 380 ENGINE_RPM ENGINE_RPM 1 0; CHFFR_METRIC 804 ENGINE_TEMPERATURE ENGINE_TEMPERATURE
CM_ "CHFFR_METRIC 330 STEER_ANGLE STEER_ANGLE 0.36 180; CHFFR_METRIC 380 ENGINE_RPM ENGINE_RPM 1 0; CHFFR_METRIC 804 ENGINE_TEMPERATURE ENGINE_TEMPERATURE";
CM_ "CHFFR_METRIC 330 STEER_ANGLE STEER_ANGLE 0.36 180; CHFFR_METRIC 380 ENGINE_RPM ENGINE_RPM 1 0; CHFFR_METRIC 804 ENGINE_TEMPERATURE ENGINE_TEMPERATURE 
CM_ "CHFFR_METRIC 330 STEER_ANGLE STEER_ANGLE 0.36 180; CHFFR_METRIC 380 ENGINE_RPM ENGINE_RPM 1 0; CHFFR_METRIC 804 ENGINE_TEMPERATURE ENGINE_TEMPERATURE ";
CM_ "CHFFR_METRIC 330 STEER_ANGLE STEER_ANGLE 0.36 180; CHFFR_METRIC 380 ENGINE_RPM ENGINE_RPM 1 0; CHFFR_METRIC 804 ENGINE_TEMPERATURE ENGINE_TEMPERATURE 1
CM_ "CHFFR_METRIC 330 STEER_ANGLE STEER_ANGLE 0.36 180; CHFFR_METRIC 380 ENGINE_RPM ENGINE_RPM 1 0; CHFFR_METRIC 804 ENGINE_TEMPERATURE ENGINE_TEMPERATUR";
CM_ "CHFFR_METRIC 330 STEER_ANGLE STEER_ANGLE 0.36 180; CHFFR_METRIC 380 ENGINE_RPM ENGINE_RPM 1 0; CHFFR_METRIC 804 ENGINE_TEMPERATURE ENGINE_TEMPERATURE
CM_ "CHFFR_METRIC 330 STEER_ANGLE STEER_ANGLE 0.36 180; CHFFR_METRIC 380 ENGINE_RPM ENGINE_RPM 1 0; CHFFR_METRIC 804 ENGINE_TEMPERATURE ENGINE_TEMPERATUR";
CM_ "CHFFR_METRIC 330 STEER_ANGLE STEER_ANGLE 0.36 180; CHFFR_METRIC 380 ENGINE_RPM ENGINE_RPM 1 0; CHFFR_METRIC 804 ENGINE_TEMPERATURE ENGINE_TEMPERATURE
CM_ "CHFFR_METRIC 330 STEER_ANGLE STEER_ANGLE 0.36 180; CHFFR_METRIC 380 ENGINE_RPM ENGINE_RPM 1 0; CHFFR_METRIC 804 ENGINE_TEMPERATURE ENGINE_TEMPERATURE";
CM_ "CHFFR_METRIC 330 STEER_ANGLE STEER_ANGLE 0.36 180; CHFFR_METRIC 380 ENGINE_RPM ENGINE_RPM 1 0; CHFFR_METRIC 804 ENGINE_TEMPERATURE ENGINE_TEMPERATURE 
CM_ "CHFFR_METRIC 330 STEER_ANGLE STEER_ANGLE 0.36 180; CHFFR_METRIC 380 ENGINE_RPM ENGINE_RPM 1 0; CHFFR_METRIC 804 ENGINE_TEMPERATURE ENGINE_TEMPERATURE ";
CM_ "CHFFR_METRIC 330 STEER_ANGLE STEER_ANGLE 0.36 180; CHFFR_METRIC 380 ENGINE_RPM ENGINE_RPM 1 0; CHFFR_METRIC 804 ENGINE_TEMPERATURE ENGINE_TEMPERATURE 1
CM_ "CHFFR_METRIC 330 STEER_ANGLE STEER_ANGLE 0.36 180; CHFFR_METRIC 380 ENGINE_RPM ENGINE_RPM 1 0; CHFFR_METRIC 804 ENGINE_TEMPERATURE ENGINE_TEMPERATURE";
CM_ "CHFFR_METRIC 330 STEER_ANGLE STEER_ANGLE 0.36 180; CHFFR_METRIC 380 ENGINE_RPM ENGINE_RPM 1 0; CHFFR_METRIC 804 ENGINE_TEMPERATURE ENGINE_TEMPERATURE 
CM_ "CHFFR_METRIC 330 STEER_ANGLE STEER_ANGLE 0.36 180; CHFFR_METRIC 380 ENGINE_RPM ENGINE_RPM 1 0; CHFFR_METRIC 804 ENGINE_TEMPERATURE ENGINE_TEMPERATURE ";
CM_ "CHFFR_METRIC 330 STEER_ANGLE STEER_ANGLE 0.36 180; CHFFR_METRIC 380 ENGINE_RPM ENGINE_RPM 1 0; CHFFR_METRIC 804 ENGINE_TEMPERATURE ENGINE_TEMPERATURE 1
CM_ "CHFFR_METRIC 330 STEER_ANGLE STEER_ANGLE 0.36 180; CHFFR_METRIC 380 ENGINE_RPM ENGINE_RPM 1 0; CHFFR_METRIC 804 ENGINE_TEMPERATURE ENGINE_TEMPERATURE";
CM_ "CHFFR_METRIC 330 STEER_ANGLE STEER_ANGLE 0.36 180; CHFFR_METRIC 380 ENGINE_RPM ENGINE_RPM 1 0; CHFFR_METRIC 804 ENGINE_TEMPERATURE ENGINE_TEMPERATURE 
CM_ "CHFFR_METRIC 330 STEER_ANGLE STEER_ANGLE 0.36 180; CHFFR_METRIC 380 ENGINE_RPM ENGINE_RPM 1 0; CHFFR_METRIC 804 ENGINE_TEMPERATURE ENGINE_TEMPERATURE ";
CM_ "CHFFR_METRIC 330 STEER_ANGLE STEER_ANGLE 0.36 180; CHFFR_METRIC 380 ENGINE_RPM ENGINE_RPM 1 0; CHFFR_METRIC 804 ENGINE_TEMPERATURE ENGINE_TEMPERATURE 1
CM_ "CHFFR_METRIC 330 STEER_ANGLE STEER_ANGLE 0.36 180; CHFFR_METRIC 380 ENGINE_RPM ENGINE_RPM 1 0; CHFFR_METRIC 804 ENGINE_TEMPERATURE ENGINE_TEMPERATURE ";
CM_ "CHFFR_METRIC 330 STEER_ANGLE STEER_ANGLE 0.36 180; CHFFR_METRIC 380 ENGINE_RPM ENGINE_RPM 1 0; CHFFR_METRIC 804 ENGINE_TEMPERATURE ENGINE_TEMPERATURE 1
CM_ "CHFFR_METRIC 330 STEER_ANGLE STEER_ANGLE 0.36 180; CHFFR_METRIC 380 ENGINE_RPM ENGINE_RPM 1 0; CHFFR_METRIC 804 ENGINE_TEMPERATURE ENGINE_TEMPERATURE ";
CM_ "CHFFR_METRIC 330 STEER_ANGLE STEER_ANGLE 0.36 180; CHFFR_METRIC 380 ENGINE_RPM ENGINE_RPM 1 0; CHFFR_METRIC 804 ENGINE_TEMPERATURE ENGINE_TEMPERATURE 1
CM_ "CHFFR_METRIC 330 STEER_ANGLE STEER_ANGLE 0.36 180; CHFFR_METRIC 380 ENGINE_RPM ENGINE_RPM 1 0; CHFFR_METRIC 804 ENGINE_TEMPERATURE ENGINE_TEMPERATURE 1";
CM_ "CHFFR_METRIC 330 STEER_ANGLE STEER_ANGLE 0.36 180; CHFFR_METRIC 380 ENGINE_RPM ENGINE_RPM 1 0; CHFFR_METRIC 804 ENGINE_TEMPERATURE ENGINE_TEMPERATURE 1 
CM_ "CHFFR_METRIC 330 STEER_ANGLE STEER_ANGLE 0.36 180; CHFFR_METRIC 380 ENGINE_RPM ENGINE_RPM 1 0; CHFFR_METRIC 804 ENGINE_TEMPERATURE ENGINE_TEMPERATURE 1 ";
CM_ "CHFFR_METRIC 330 STEER_ANGLE STEER_ANGLE 0.36 180; CHFFR_METRIC 380 ENGINE_RPM ENGINE_RPM 1 0; CHFFR_METRIC 804 ENGINE_TEMPERATURE ENGINE_TEMPERATURE 1 0";
